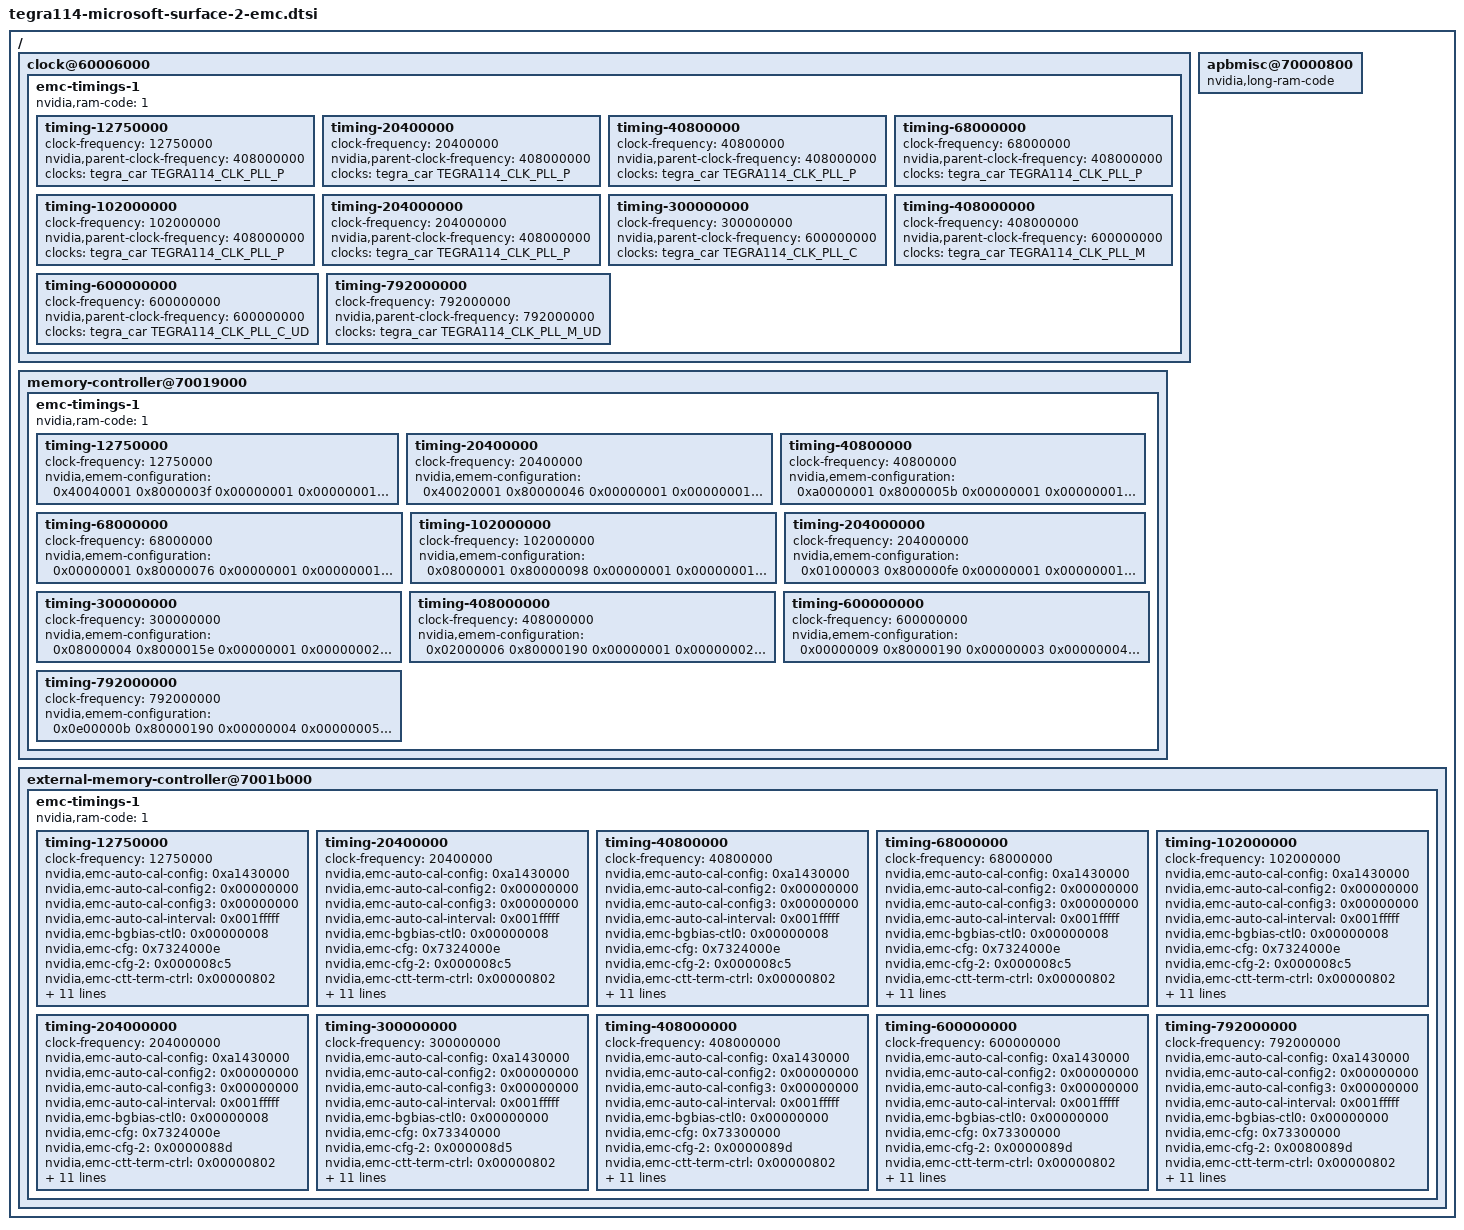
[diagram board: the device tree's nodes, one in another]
// SPDX-License-Identifier: GPL-2.0

#include <dt-bindings/clock/tegra114-car.h>

/ {
	clock@60006000 {
		emc-timings-1 {
			nvidia,ram-code = <1>;

			timing-12750000 {
				clock-frequency = <12750000>;
				nvidia,parent-clock-frequency = <408000000>;
				clocks = <&tegra_car TEGRA114_CLK_PLL_P>;
				clock-names = "emc-parent";
			};

			timing-20400000 {
				clock-frequency = <20400000>;
				nvidia,parent-clock-frequency = <408000000>;
				clocks = <&tegra_car TEGRA114_CLK_PLL_P>;
				clock-names = "emc-parent";
			};

			timing-40800000 {
				clock-frequency = <40800000>;
				nvidia,parent-clock-frequency = <408000000>;
				clocks = <&tegra_car TEGRA114_CLK_PLL_P>;
				clock-names = "emc-parent";
			};

			timing-68000000 {
				clock-frequency = <68000000>;
				nvidia,parent-clock-frequency = <408000000>;
				clocks = <&tegra_car TEGRA114_CLK_PLL_P>;
				clock-names = "emc-parent";
			};

			timing-102000000 {
				clock-frequency = <102000000>;
				nvidia,parent-clock-frequency = <408000000>;
				clocks = <&tegra_car TEGRA114_CLK_PLL_P>;
				clock-names = "emc-parent";
			};

			timing-204000000 {
				clock-frequency = <204000000>;
				nvidia,parent-clock-frequency = <408000000>;
				clocks = <&tegra_car TEGRA114_CLK_PLL_P>;
				clock-names = "emc-parent";
			};

			timing-300000000 {
				clock-frequency = <300000000>;
				nvidia,parent-clock-frequency = <600000000>;
				clocks = <&tegra_car TEGRA114_CLK_PLL_C>;
				clock-names = "emc-parent";
			};

			timing-408000000 {
				clock-frequency = <408000000>;
				nvidia,parent-clock-frequency = <600000000>;
				clocks = <&tegra_car TEGRA114_CLK_PLL_M>;
				clock-names = "emc-parent";
			};

			timing-600000000 {
				clock-frequency = <600000000>;
				nvidia,parent-clock-frequency = <600000000>;
				clocks = <&tegra_car TEGRA114_CLK_PLL_C_UD>;
				clock-names = "emc-parent";
			};

			timing-792000000 {
				clock-frequency = <792000000>;
				nvidia,parent-clock-frequency = <792000000>;
				clocks = <&tegra_car TEGRA114_CLK_PLL_M_UD>;
				clock-names = "emc-parent";
			};
		};

	};

	apbmisc@70000800 {
		nvidia,long-ram-code;
	};

	memory-controller@70019000 {
		emc-timings-1 {
			nvidia,ram-code = <1>;

			timing-12750000 {
				clock-frequency = <12750000>;

				nvidia,emem-configuration = <
			0x40040001	/* MC_EMEM_ARB_CFG */
			0x8000003f	/* MC_EMEM_ARB_OUTSTANDING_REQ */
			0x00000001	/* MC_EMEM_ARB_TIMING_RCD */
			0x00000001	/* MC_EMEM_ARB_TIMING_RP */
			0x00000002	/* MC_EMEM_ARB_TIMING_RC */
			0x00000000	/* MC_EMEM_ARB_TIMING_RAS */
			0x00000001	/* MC_EMEM_ARB_TIMING_FAW */
			0x00000001	/* MC_EMEM_ARB_TIMING_RRD */
			0x00000002	/* MC_EMEM_ARB_TIMING_RAP2PRE */
			0x00000008	/* MC_EMEM_ARB_TIMING_WAP2PRE */
			0x00000002	/* MC_EMEM_ARB_TIMING_R2R */
			0x00000001	/* MC_EMEM_ARB_TIMING_W2W */
			0x00000003	/* MC_EMEM_ARB_TIMING_R2W */
			0x00000006	/* MC_EMEM_ARB_TIMING_W2R */
			0x06030102	/* MC_EMEM_ARB_DA_TURNS */
			0x000a0402	/* MC_EMEM_ARB_DA_COVERS */
			0x77e30303	/* MC_EMEM_ARB_MISC0 */
			0x001f0000	/* MC_EMEM_ARB_RING1_THROTTLE */
				>;
			};

			timing-20400000 {
				clock-frequency = <20400000>;

				nvidia,emem-configuration = <
			0x40020001	/* MC_EMEM_ARB_CFG */
			0x80000046	/* MC_EMEM_ARB_OUTSTANDING_REQ */
			0x00000001	/* MC_EMEM_ARB_TIMING_RCD */
			0x00000001	/* MC_EMEM_ARB_TIMING_RP */
			0x00000002	/* MC_EMEM_ARB_TIMING_RC */
			0x00000000	/* MC_EMEM_ARB_TIMING_RAS */
			0x00000001	/* MC_EMEM_ARB_TIMING_FAW */
			0x00000001	/* MC_EMEM_ARB_TIMING_RRD */
			0x00000002	/* MC_EMEM_ARB_TIMING_RAP2PRE */
			0x00000008	/* MC_EMEM_ARB_TIMING_WAP2PRE */
			0x00000002	/* MC_EMEM_ARB_TIMING_R2R */
			0x00000001	/* MC_EMEM_ARB_TIMING_W2W */
			0x00000003	/* MC_EMEM_ARB_TIMING_R2W */
			0x00000006	/* MC_EMEM_ARB_TIMING_W2R */
			0x06030102	/* MC_EMEM_ARB_DA_TURNS */
			0x000a0402	/* MC_EMEM_ARB_DA_COVERS */
			0x76230303	/* MC_EMEM_ARB_MISC0 */
			0x001f0000	/* MC_EMEM_ARB_RING1_THROTTLE */
				>;
			};

			timing-40800000 {
				clock-frequency = <40800000>;

				nvidia,emem-configuration = <
			0xa0000001	/* MC_EMEM_ARB_CFG */
			0x8000005b	/* MC_EMEM_ARB_OUTSTANDING_REQ */
			0x00000001	/* MC_EMEM_ARB_TIMING_RCD */
			0x00000001	/* MC_EMEM_ARB_TIMING_RP */
			0x00000002	/* MC_EMEM_ARB_TIMING_RC */
			0x00000000	/* MC_EMEM_ARB_TIMING_RAS */
			0x00000001	/* MC_EMEM_ARB_TIMING_FAW */
			0x00000001	/* MC_EMEM_ARB_TIMING_RRD */
			0x00000002	/* MC_EMEM_ARB_TIMING_RAP2PRE */
			0x00000008	/* MC_EMEM_ARB_TIMING_WAP2PRE */
			0x00000002	/* MC_EMEM_ARB_TIMING_R2R */
			0x00000001	/* MC_EMEM_ARB_TIMING_W2W */
			0x00000003	/* MC_EMEM_ARB_TIMING_R2W */
			0x00000006	/* MC_EMEM_ARB_TIMING_W2R */
			0x06030102	/* MC_EMEM_ARB_DA_TURNS */
			0x000a0402	/* MC_EMEM_ARB_DA_COVERS */
			0x74a30303	/* MC_EMEM_ARB_MISC0 */
			0x001f0000	/* MC_EMEM_ARB_RING1_THROTTLE */
				>;
			};

			timing-68000000 {
				clock-frequency = <68000000>;

				nvidia,emem-configuration = <
			0x00000001	/* MC_EMEM_ARB_CFG */
			0x80000076	/* MC_EMEM_ARB_OUTSTANDING_REQ */
			0x00000001	/* MC_EMEM_ARB_TIMING_RCD */
			0x00000001	/* MC_EMEM_ARB_TIMING_RP */
			0x00000002	/* MC_EMEM_ARB_TIMING_RC */
			0x00000000	/* MC_EMEM_ARB_TIMING_RAS */
			0x00000001	/* MC_EMEM_ARB_TIMING_FAW */
			0x00000001	/* MC_EMEM_ARB_TIMING_RRD */
			0x00000002	/* MC_EMEM_ARB_TIMING_RAP2PRE */
			0x00000008	/* MC_EMEM_ARB_TIMING_WAP2PRE */
			0x00000002	/* MC_EMEM_ARB_TIMING_R2R */
			0x00000001	/* MC_EMEM_ARB_TIMING_W2W */
			0x00000003	/* MC_EMEM_ARB_TIMING_R2W */
			0x00000006	/* MC_EMEM_ARB_TIMING_W2R */
			0x06030102	/* MC_EMEM_ARB_DA_TURNS */
			0x000a0402	/* MC_EMEM_ARB_DA_COVERS */
			0x74230403	/* MC_EMEM_ARB_MISC0 */
			0x001f0000	/* MC_EMEM_ARB_RING1_THROTTLE */
				>;
			};

			timing-102000000 {
				clock-frequency = <102000000>;

				nvidia,emem-configuration = <
			0x08000001	/* MC_EMEM_ARB_CFG */
			0x80000098	/* MC_EMEM_ARB_OUTSTANDING_REQ */
			0x00000001	/* MC_EMEM_ARB_TIMING_RCD */
			0x00000001	/* MC_EMEM_ARB_TIMING_RP */
			0x00000003	/* MC_EMEM_ARB_TIMING_RC */
			0x00000000	/* MC_EMEM_ARB_TIMING_RAS */
			0x00000002	/* MC_EMEM_ARB_TIMING_FAW */
			0x00000001	/* MC_EMEM_ARB_TIMING_RRD */
			0x00000002	/* MC_EMEM_ARB_TIMING_RAP2PRE */
			0x00000008	/* MC_EMEM_ARB_TIMING_WAP2PRE */
			0x00000002	/* MC_EMEM_ARB_TIMING_R2R */
			0x00000001	/* MC_EMEM_ARB_TIMING_W2W */
			0x00000003	/* MC_EMEM_ARB_TIMING_R2W */
			0x00000006	/* MC_EMEM_ARB_TIMING_W2R */
			0x06030102	/* MC_EMEM_ARB_DA_TURNS */
			0x000a0403	/* MC_EMEM_ARB_DA_COVERS */
			0x73c30504	/* MC_EMEM_ARB_MISC0 */
			0x001f0000	/* MC_EMEM_ARB_RING1_THROTTLE */
				>;
			};

			timing-204000000 {
				clock-frequency = <204000000>;

				nvidia,emem-configuration = <
			0x01000003	/* MC_EMEM_ARB_CFG */
			0x800000fe	/* MC_EMEM_ARB_OUTSTANDING_REQ */
			0x00000001	/* MC_EMEM_ARB_TIMING_RCD */
			0x00000001	/* MC_EMEM_ARB_TIMING_RP */
			0x00000005	/* MC_EMEM_ARB_TIMING_RC */
			0x00000002	/* MC_EMEM_ARB_TIMING_RAS */
			0x00000004	/* MC_EMEM_ARB_TIMING_FAW */
			0x00000001	/* MC_EMEM_ARB_TIMING_RRD */
			0x00000002	/* MC_EMEM_ARB_TIMING_RAP2PRE */
			0x00000008	/* MC_EMEM_ARB_TIMING_WAP2PRE */
			0x00000002	/* MC_EMEM_ARB_TIMING_R2R */
			0x00000001	/* MC_EMEM_ARB_TIMING_W2W */
			0x00000003	/* MC_EMEM_ARB_TIMING_R2W */
			0x00000006	/* MC_EMEM_ARB_TIMING_W2R */
			0x06030102	/* MC_EMEM_ARB_DA_TURNS */
			0x000a0405	/* MC_EMEM_ARB_DA_COVERS */
			0x73840a06	/* MC_EMEM_ARB_MISC0 */
			0x001f0000	/* MC_EMEM_ARB_RING1_THROTTLE */
				>;
			};

			timing-300000000 {
				clock-frequency = <300000000>;

				nvidia,emem-configuration = <
			0x08000004	/* MC_EMEM_ARB_CFG */
			0x8000015e	/* MC_EMEM_ARB_OUTSTANDING_REQ */
			0x00000001	/* MC_EMEM_ARB_TIMING_RCD */
			0x00000002	/* MC_EMEM_ARB_TIMING_RP */
			0x00000007	/* MC_EMEM_ARB_TIMING_RC */
			0x00000004	/* MC_EMEM_ARB_TIMING_RAS */
			0x00000005	/* MC_EMEM_ARB_TIMING_FAW */
			0x00000001	/* MC_EMEM_ARB_TIMING_RRD */
			0x00000002	/* MC_EMEM_ARB_TIMING_RAP2PRE */
			0x00000007	/* MC_EMEM_ARB_TIMING_WAP2PRE */
			0x00000002	/* MC_EMEM_ARB_TIMING_R2R */
			0x00000002	/* MC_EMEM_ARB_TIMING_W2W */
			0x00000004	/* MC_EMEM_ARB_TIMING_R2W */
			0x00000006	/* MC_EMEM_ARB_TIMING_W2R */
			0x06040202	/* MC_EMEM_ARB_DA_TURNS */
			0x000b0607	/* MC_EMEM_ARB_DA_COVERS */
			0x77450e08	/* MC_EMEM_ARB_MISC0 */
			0x001f0000	/* MC_EMEM_ARB_RING1_THROTTLE */
				>;
			};


			timing-408000000 {
				clock-frequency = <408000000>;

				nvidia,emem-configuration = <
			0x02000006	/* MC_EMEM_ARB_CFG */
			0x80000190	/* MC_EMEM_ARB_OUTSTANDING_REQ */
			0x00000001	/* MC_EMEM_ARB_TIMING_RCD */
			0x00000002	/* MC_EMEM_ARB_TIMING_RP */
			0x0000000a	/* MC_EMEM_ARB_TIMING_RC */
			0x00000006	/* MC_EMEM_ARB_TIMING_RAS */
			0x00000008	/* MC_EMEM_ARB_TIMING_FAW */
			0x00000001	/* MC_EMEM_ARB_TIMING_RRD */
			0x00000002	/* MC_EMEM_ARB_TIMING_RAP2PRE */
			0x00000009	/* MC_EMEM_ARB_TIMING_WAP2PRE */
			0x00000002	/* MC_EMEM_ARB_TIMING_R2R */
			0x00000002	/* MC_EMEM_ARB_TIMING_W2W */
			0x00000004	/* MC_EMEM_ARB_TIMING_R2W */
			0x00000006	/* MC_EMEM_ARB_TIMING_W2R */
			0x06040202	/* MC_EMEM_ARB_DA_TURNS */
			0x000e070a	/* MC_EMEM_ARB_DA_COVERS */
			0x7547130b	/* MC_EMEM_ARB_MISC0 */
			0x001f0000	/* MC_EMEM_ARB_RING1_THROTTLE */
				>;
			};

			timing-600000000 {
				clock-frequency = <600000000>;

				nvidia,emem-configuration = <
			0x00000009	/* MC_EMEM_ARB_CFG */
			0x80000190	/* MC_EMEM_ARB_OUTSTANDING_REQ */
			0x00000003	/* MC_EMEM_ARB_TIMING_RCD */
			0x00000004	/* MC_EMEM_ARB_TIMING_RP */
			0x0000000e	/* MC_EMEM_ARB_TIMING_RC */
			0x00000009	/* MC_EMEM_ARB_TIMING_RAS */
			0x0000000b	/* MC_EMEM_ARB_TIMING_FAW */
			0x00000001	/* MC_EMEM_ARB_TIMING_RRD */
			0x00000003	/* MC_EMEM_ARB_TIMING_RAP2PRE */
			0x0000000b	/* MC_EMEM_ARB_TIMING_WAP2PRE */
			0x00000002	/* MC_EMEM_ARB_TIMING_R2R */
			0x00000002	/* MC_EMEM_ARB_TIMING_W2W */
			0x00000005	/* MC_EMEM_ARB_TIMING_R2W */
			0x00000007	/* MC_EMEM_ARB_TIMING_W2R */
			0x07050202	/* MC_EMEM_ARB_DA_TURNS */
			0x00130b0e	/* MC_EMEM_ARB_DA_COVERS */
			0x73a91b0f	/* MC_EMEM_ARB_MISC0 */
			0x001f0000	/* MC_EMEM_ARB_RING1_THROTTLE */
				>;
			};

			timing-792000000 {
				clock-frequency = <792000000>;

				nvidia,emem-configuration = <
			0x0e00000b	/* MC_EMEM_ARB_CFG */
			0x80000190	/* MC_EMEM_ARB_OUTSTANDING_REQ */
			0x00000004	/* MC_EMEM_ARB_TIMING_RCD */
			0x00000005	/* MC_EMEM_ARB_TIMING_RP */
			0x00000013	/* MC_EMEM_ARB_TIMING_RC */
			0x0000000c	/* MC_EMEM_ARB_TIMING_RAS */
			0x0000000f	/* MC_EMEM_ARB_TIMING_FAW */
			0x00000002	/* MC_EMEM_ARB_TIMING_RRD */
			0x00000003	/* MC_EMEM_ARB_TIMING_RAP2PRE */
			0x0000000c	/* MC_EMEM_ARB_TIMING_WAP2PRE */
			0x00000002	/* MC_EMEM_ARB_TIMING_R2R */
			0x00000002	/* MC_EMEM_ARB_TIMING_W2W */
			0x00000006	/* MC_EMEM_ARB_TIMING_R2W */
			0x00000008	/* MC_EMEM_ARB_TIMING_W2R */
			0x08060202	/* MC_EMEM_ARB_DA_TURNS */
			0x00160d13	/* MC_EMEM_ARB_DA_COVERS */
			0x734c2414	/* MC_EMEM_ARB_MISC0 */
			0x001f0000	/* MC_EMEM_ARB_RING1_THROTTLE */
				>;
			};
		};

	};

	external-memory-controller@7001b000 {
		emc-timings-1 {
			nvidia,ram-code = <1>;

			timing-12750000 {
				clock-frequency = <12750000>;

				nvidia,emc-auto-cal-config = <0xa1430000>;
				nvidia,emc-auto-cal-config2 = <0x00000000>;
				nvidia,emc-auto-cal-config3 = <0x00000000>;
				nvidia,emc-auto-cal-interval = <0x001fffff>;
				nvidia,emc-bgbias-ctl0 = <0x00000008>;
				nvidia,emc-cfg = <0x7324000e>;
				nvidia,emc-cfg-2 = <0x000008c5>;
				nvidia,emc-ctt-term-ctrl = <0x00000802>;
				nvidia,emc-mode-1 = <0x80100003>;
				nvidia,emc-mode-2 = <0x80200048>;
				nvidia,emc-mode-4 = <0x00000000>;
				nvidia,emc-mode-reset = <0x80001221>;
				nvidia,emc-mrs-wait-cnt = <0x000c000c>;
				nvidia,emc-sel-dpd-ctrl = <0x00040128>;
				nvidia,emc-xm2dqspadctrl2 = <0x0130b118>;
				nvidia,emc-zcal-cnt-long = <0x00000042>;
				nvidia,emc-zcal-interval = <0x00000000>;

				nvidia,emc-configuration = <
			0x00000000	/* EMC_RC */
			0x00000003	/* EMC_RFC */
			0x00000000	/* EMC_RFC_SLR */
			0x00000000	/* EMC_RAS */
			0x00000000	/* EMC_RP */
			0x00000004	/* EMC_R2W */
			0x0000000a	/* EMC_W2R */
			0x00000003	/* EMC_R2P */
			0x0000000b	/* EMC_W2P */
			0x00000000	/* EMC_RD_RCD */
			0x00000000	/* EMC_WR_RCD */
			0x00000003	/* EMC_RRD */
			0x00000001	/* EMC_REXT */
			0x00000000	/* EMC_WEXT */
			0x00000005	/* EMC_WDV */
			0x0000000f	/* EMC_WDV_MASK */
			0x00000006	/* EMC_IBDLY */
			0x00010000	/* EMC_PUTERM_EXTRA */
			0x00000000	/* EMC_CDB_CNTL_2 */
			0x00000004	/* EMC_QRST */
			0x0000000f	/* EMC_RDV_MASK */
			0x00000060	/* EMC_REFRESH */
			0x00000000	/* EMC_BURST_REFRESH_NUM */
			0x00000018	/* EMC_PRE_REFRESH_REQ_CNT */
			0x00000002	/* EMC_PDEX2WR */
			0x00000002	/* EMC_PDEX2RD */
			0x00000001	/* EMC_PCHG2PDEN */
			0x00000000	/* EMC_ACT2PDEN */
			0x00000007	/* EMC_AR2PDEN */
			0x0000000f	/* EMC_RW2PDEN */
			0x00000005	/* EMC_TXSR */
			0x00000005	/* EMC_TXSRDLL */
			0x00000004	/* EMC_TCKE */
			0x00000004	/* EMC_TCKESR */
			0x00000004	/* EMC_TPD */
			0x00000004	/* EMC_TFAW */
			0x00000000	/* EMC_TRPAB */
			0x00000004	/* EMC_TCLKSTABLE */
			0x00000005	/* EMC_TCLKSTOP */
			0x00000064	/* EMC_TREFBW */
			0x00000006	/* EMC_QUSE_EXTRA */
			0x00000020	/* EMC_ODT_WRITE */
			0x00000000	/* EMC_ODT_READ */
			0x0000aa88	/* EMC_FBIO_CFG5 */
			0x002c00a0	/* EMC_CFG_DIG_DLL */
			0x00008000	/* EMC_CFG_DIG_DLL_PERIOD */
			0x00078000	/* EMC_DLL_XFORM_DQS4 */
			0x00078000	/* EMC_DLL_XFORM_DQS5 */
			0x00078000	/* EMC_DLL_XFORM_DQS6 */
			0x00078000	/* EMC_DLL_XFORM_DQS7 */
			0x00000000	/* EMC_DLL_XFORM_QUSE4 */
			0x00000000	/* EMC_DLL_XFORM_QUSE5 */
			0x00000000	/* EMC_DLL_XFORM_QUSE6 */
			0x00000000	/* EMC_DLL_XFORM_QUSE7 */
			0x00000000	/* EMC_DLI_TRIM_TXDQS4 */
			0x00000000	/* EMC_DLI_TRIM_TXDQS5 */
			0x00000000	/* EMC_DLI_TRIM_TXDQS6 */
			0x00000000	/* EMC_DLI_TRIM_TXDQS7 */
			0x001112a0	/* EMC_XM2CMDPADCTRL */
			0x00000000	/* EMC_XM2CMDPADCTRL4 */
			0x0000a11c	/* EMC_XM2DQSPADCTRL2 */
			0x00000000	/* EMC_XM2DQPADCTRL2 */
			0x77ffc085	/* EMC_XM2CLKPADCTRL */
			0x81f1f108	/* EMC_XM2COMPPADCTRL */
			0x03037504	/* EMC_XM2VTTGENPADCTRL */
			0x0000003f	/* EMC_XM2VTTGENPADCTRL2 */
			0x0000003f	/* EMC_DSR_VTTGEN_DRV */
			0x00000007	/* EMC_TXDSRVTTGEN */
			0x02000000	/* EMC_FBIO_SPARE */
			0x00000802	/* EMC_CTT_TERM_CTRL */
			0x00000000	/* EMC_ZCAL_INTERVAL */
			0x00000042	/* EMC_ZCAL_WAIT_CNT */
			0x000c000c	/* EMC_MRS_WAIT_CNT */
			0x000c000c	/* EMC_MRS_WAIT_CNT2 */
			0x00000000	/* EMC_AUTO_CAL_CONFIG2 */
			0x00000000	/* EMC_AUTO_CAL_CONFIG3 */
			0x00000000	/* EMC_CTT */
			0x00000000	/* EMC_CTT_DURATION */
			0x800001c5	/* EMC_DYN_SELF_REF_CONTROL */
			0x1f7df7df	/* EMC_CA_TRAINING_TIMING_CNTL1 */
			0x0000001f	/* EMC_CA_TRAINING_TIMING_CNTL2 */
			0x00040320	/* EMC_SEL_DPD_CTRL */
			0x00000000	/* EMC_CDB_CNTL_1 */
			0x00000004	/* EMC_FBIO_CFG6 */
			0x00000007	/* EMC_QUSE */
			0x00000004	/* EMC_EINPUT */
			0x00000004	/* EMC_EINPUT_DURATION */
			0x00078000	/* EMC_DLL_XFORM_DQS0 */
			0x00000009	/* EMC_QSAFE */
			0x00000000	/* EMC_DLL_XFORM_QUSE0 */
			0x0000000d	/* EMC_RDV */
			0x00249249	/* EMC_XM2DQSPADCTRL4 */
			0x20820800	/* EMC_XM2DQSPADCTRL3 */
			0x0007c000	/* EMC_DLL_XFORM_DQ0 */
			0xa0f10f0f	/* EMC_AUTO_CAL_CONFIG */
			0x00000000	/* EMC_DLL_XFORM_ADDR0 */
			0x00000d0d	/* EMC_XM2CLKPADCTRL2 */
			0x00000000	/* EMC_DLI_TRIM_TXDQS0 */
			0x00000000	/* EMC_DLL_XFORM_ADDR1 */
			0x00000000	/* EMC_DLL_XFORM_ADDR2 */
			0x00078000	/* EMC_DLL_XFORM_DQS1 */
			0x00078000	/* EMC_DLL_XFORM_DQS2 */
			0x00078000	/* EMC_DLL_XFORM_DQS3 */
			0x0007c000	/* EMC_DLL_XFORM_DQ1 */
			0x0007c000	/* EMC_DLL_XFORM_DQ2 */
			0x0007c000	/* EMC_DLL_XFORM_DQ3 */
			0x00000000	/* EMC_DLI_TRIM_TXDQS1 */
			0x00000000	/* EMC_DLI_TRIM_TXDQS2 */
			0x00000000	/* EMC_DLI_TRIM_TXDQS3 */
			0x00000000	/* EMC_DLL_XFORM_QUSE1 */
			0x00000000	/* EMC_DLL_XFORM_QUSE2 */
			0x00000000	/* EMC_DLL_XFORM_QUSE3 */
				>;
			};

			timing-20400000 {
				clock-frequency = <20400000>;

				nvidia,emc-auto-cal-config = <0xa1430000>;
				nvidia,emc-auto-cal-config2 = <0x00000000>;
				nvidia,emc-auto-cal-config3 = <0x00000000>;
				nvidia,emc-auto-cal-interval = <0x001fffff>;
				nvidia,emc-bgbias-ctl0 = <0x00000008>;
				nvidia,emc-cfg = <0x7324000e>;
				nvidia,emc-cfg-2 = <0x000008c5>;
				nvidia,emc-ctt-term-ctrl = <0x00000802>;
				nvidia,emc-mode-1 = <0x80100003>;
				nvidia,emc-mode-2 = <0x80200048>;
				nvidia,emc-mode-4 = <0x00000000>;
				nvidia,emc-mode-reset = <0x80001221>;
				nvidia,emc-mrs-wait-cnt = <0x000c000c>;
				nvidia,emc-sel-dpd-ctrl = <0x00040128>;
				nvidia,emc-xm2dqspadctrl2 = <0x0130b118>;
				nvidia,emc-zcal-cnt-long = <0x00000042>;
				nvidia,emc-zcal-interval = <0x00000000>;

				nvidia,emc-configuration = <
							0x00000000	/* EMC_RC */
			0x00000005	/* EMC_RFC */
			0x00000000	/* EMC_RFC_SLR */
			0x00000000	/* EMC_RAS */
			0x00000000	/* EMC_RP */
			0x00000004	/* EMC_R2W */
			0x0000000a	/* EMC_W2R */
			0x00000003	/* EMC_R2P */
			0x0000000b	/* EMC_W2P */
			0x00000000	/* EMC_RD_RCD */
			0x00000000	/* EMC_WR_RCD */
			0x00000003	/* EMC_RRD */
			0x00000001	/* EMC_REXT */
			0x00000000	/* EMC_WEXT */
			0x00000005	/* EMC_WDV */
			0x0000000f	/* EMC_WDV_MASK */
			0x00000006	/* EMC_IBDLY */
			0x00010000	/* EMC_PUTERM_EXTRA */
			0x00000000	/* EMC_CDB_CNTL_2 */
			0x00000004	/* EMC_QRST */
			0x0000000f	/* EMC_RDV_MASK */
			0x0000009a	/* EMC_REFRESH */
			0x00000000	/* EMC_BURST_REFRESH_NUM */
			0x00000026	/* EMC_PRE_REFRESH_REQ_CNT */
			0x00000002	/* EMC_PDEX2WR */
			0x00000002	/* EMC_PDEX2RD */
			0x00000001	/* EMC_PCHG2PDEN */
			0x00000000	/* EMC_ACT2PDEN */
			0x00000007	/* EMC_AR2PDEN */
			0x0000000f	/* EMC_RW2PDEN */
			0x00000006	/* EMC_TXSR */
			0x00000006	/* EMC_TXSRDLL */
			0x00000004	/* EMC_TCKE */
			0x00000004	/* EMC_TCKESR */
			0x00000004	/* EMC_TPD */
			0x00000004	/* EMC_TFAW */
			0x00000000	/* EMC_TRPAB */
			0x00000004	/* EMC_TCLKSTABLE */
			0x00000005	/* EMC_TCLKSTOP */
			0x000000a0	/* EMC_TREFBW */
			0x00000006	/* EMC_QUSE_EXTRA */
			0x00000020	/* EMC_ODT_WRITE */
			0x00000000	/* EMC_ODT_READ */
			0x0000aa88	/* EMC_FBIO_CFG5 */
			0x002c00a0	/* EMC_CFG_DIG_DLL */
			0x00008000	/* EMC_CFG_DIG_DLL_PERIOD */
			0x00078000	/* EMC_DLL_XFORM_DQS4 */
			0x00078000	/* EMC_DLL_XFORM_DQS5 */
			0x00078000	/* EMC_DLL_XFORM_DQS6 */
			0x00078000	/* EMC_DLL_XFORM_DQS7 */
			0x00000000	/* EMC_DLL_XFORM_QUSE4 */
			0x00000000	/* EMC_DLL_XFORM_QUSE5 */
			0x00000000	/* EMC_DLL_XFORM_QUSE6 */
			0x00000000	/* EMC_DLL_XFORM_QUSE7 */
			0x00000000	/* EMC_DLI_TRIM_TXDQS4 */
			0x00000000	/* EMC_DLI_TRIM_TXDQS5 */
			0x00000000	/* EMC_DLI_TRIM_TXDQS6 */
			0x00000000	/* EMC_DLI_TRIM_TXDQS7 */
			0x001112a0	/* EMC_XM2CMDPADCTRL */
			0x00000000	/* EMC_XM2CMDPADCTRL4 */
			0x0000a11c	/* EMC_XM2DQSPADCTRL2 */
			0x00000000	/* EMC_XM2DQPADCTRL2 */
			0x77ffc085	/* EMC_XM2CLKPADCTRL */
			0x81f1f108	/* EMC_XM2COMPPADCTRL */
			0x03037504	/* EMC_XM2VTTGENPADCTRL */
			0x0000003f	/* EMC_XM2VTTGENPADCTRL2 */
			0x0000003f	/* EMC_DSR_VTTGEN_DRV */
			0x0000000b	/* EMC_TXDSRVTTGEN */
			0x02000000	/* EMC_FBIO_SPARE */
			0x00000802	/* EMC_CTT_TERM_CTRL */
			0x00000000	/* EMC_ZCAL_INTERVAL */
			0x00000042	/* EMC_ZCAL_WAIT_CNT */
			0x000c000c	/* EMC_MRS_WAIT_CNT */
			0x000c000c	/* EMC_MRS_WAIT_CNT2 */
			0x00000000	/* EMC_AUTO_CAL_CONFIG2 */
			0x00000000	/* EMC_AUTO_CAL_CONFIG3 */
			0x00000000	/* EMC_CTT */
			0x00000000	/* EMC_CTT_DURATION */
			0x8000023a	/* EMC_DYN_SELF_REF_CONTROL */
			0x1f7df7df	/* EMC_CA_TRAINING_TIMING_CNTL1 */
			0x0000001f	/* EMC_CA_TRAINING_TIMING_CNTL2 */
			0x00040320	/* EMC_SEL_DPD_CTRL */
			0x00000000	/* EMC_CDB_CNTL_1 */
			0x00000004	/* EMC_FBIO_CFG6 */
			0x00000007	/* EMC_QUSE */
			0x00000004	/* EMC_EINPUT */
			0x00000004	/* EMC_EINPUT_DURATION */
			0x00078000	/* EMC_DLL_XFORM_DQS0 */
			0x00000009	/* EMC_QSAFE */
			0x00000000	/* EMC_DLL_XFORM_QUSE0 */
			0x0000000d	/* EMC_RDV */
			0x00249249	/* EMC_XM2DQSPADCTRL4 */
			0x20820800	/* EMC_XM2DQSPADCTRL3 */
			0x0007c000	/* EMC_DLL_XFORM_DQ0 */
			0xa0f10f0f	/* EMC_AUTO_CAL_CONFIG */
			0x00000000	/* EMC_DLL_XFORM_ADDR0 */
			0x00000d0d	/* EMC_XM2CLKPADCTRL2 */
			0x00000000	/* EMC_DLI_TRIM_TXDQS0 */
			0x00000000	/* EMC_DLL_XFORM_ADDR1 */
			0x00000000	/* EMC_DLL_XFORM_ADDR2 */
			0x00078000	/* EMC_DLL_XFORM_DQS1 */
			0x00078000	/* EMC_DLL_XFORM_DQS2 */
			0x00078000	/* EMC_DLL_XFORM_DQS3 */
			0x0007c000	/* EMC_DLL_XFORM_DQ1 */
			0x0007c000	/* EMC_DLL_XFORM_DQ2 */
			0x0007c000	/* EMC_DLL_XFORM_DQ3 */
			0x00000000	/* EMC_DLI_TRIM_TXDQS1 */
			0x00000000	/* EMC_DLI_TRIM_TXDQS2 */
			0x00000000	/* EMC_DLI_TRIM_TXDQS3 */
			0x00000000	/* EMC_DLL_XFORM_QUSE1 */
			0x00000000	/* EMC_DLL_XFORM_QUSE2 */
			0x00000000	/* EMC_DLL_XFORM_QUSE3 */
				>;
			};

			timing-40800000 {
				clock-frequency = <40800000>;

				nvidia,emc-auto-cal-config = <0xa1430000>;
				nvidia,emc-auto-cal-config2 = <0x00000000>;
				nvidia,emc-auto-cal-config3 = <0x00000000>;
				nvidia,emc-auto-cal-interval = <0x001fffff>;
				nvidia,emc-bgbias-ctl0 = <0x00000008>;
				nvidia,emc-cfg = <0x7324000e>;
				nvidia,emc-cfg-2 = <0x000008c5>;
				nvidia,emc-ctt-term-ctrl = <0x00000802>;
				nvidia,emc-mode-1 = <0x80100003>;
				nvidia,emc-mode-2 = <0x80200048>;
				nvidia,emc-mode-4 = <0x00000000>;
				nvidia,emc-mode-reset = <0x80001221>;
				nvidia,emc-mrs-wait-cnt = <0x000c000c>;
				nvidia,emc-sel-dpd-ctrl = <0x00040128>;
				nvidia,emc-xm2dqspadctrl2 = <0x0130b118>;
				nvidia,emc-zcal-cnt-long = <0x00000042>;
				nvidia,emc-zcal-interval = <0x00000000>;

				nvidia,emc-configuration = <
			0x00000001	/* EMC_RC */
			0x0000000a	/* EMC_RFC */
			0x00000000	/* EMC_RFC_SLR */
			0x00000001	/* EMC_RAS */
			0x00000000	/* EMC_RP */
			0x00000004	/* EMC_R2W */
			0x0000000a	/* EMC_W2R */
			0x00000003	/* EMC_R2P */
			0x0000000b	/* EMC_W2P */
			0x00000000	/* EMC_RD_RCD */
			0x00000000	/* EMC_WR_RCD */
			0x00000003	/* EMC_RRD */
			0x00000001	/* EMC_REXT */
			0x00000000	/* EMC_WEXT */
			0x00000005	/* EMC_WDV */
			0x0000000f	/* EMC_WDV_MASK */
			0x00000006	/* EMC_IBDLY */
			0x00010000	/* EMC_PUTERM_EXTRA */
			0x00000000	/* EMC_CDB_CNTL_2 */
			0x00000004	/* EMC_QRST */
			0x0000000f	/* EMC_RDV_MASK */
			0x00000134	/* EMC_REFRESH */
			0x00000000	/* EMC_BURST_REFRESH_NUM */
			0x0000004d	/* EMC_PRE_REFRESH_REQ_CNT */
			0x00000002	/* EMC_PDEX2WR */
			0x00000002	/* EMC_PDEX2RD */
			0x00000001	/* EMC_PCHG2PDEN */
			0x00000000	/* EMC_ACT2PDEN */
			0x00000008	/* EMC_AR2PDEN */
			0x0000000f	/* EMC_RW2PDEN */
			0x0000000c	/* EMC_TXSR */
			0x0000000c	/* EMC_TXSRDLL */
			0x00000004	/* EMC_TCKE */
			0x00000004	/* EMC_TCKESR */
			0x00000004	/* EMC_TPD */
			0x00000004	/* EMC_TFAW */
			0x00000000	/* EMC_TRPAB */
			0x00000004	/* EMC_TCLKSTABLE */
			0x00000005	/* EMC_TCLKSTOP */
			0x0000013f	/* EMC_TREFBW */
			0x00000006	/* EMC_QUSE_EXTRA */
			0x00000020	/* EMC_ODT_WRITE */
			0x00000000	/* EMC_ODT_READ */
			0x0000aa88	/* EMC_FBIO_CFG5 */
			0x002c00a0	/* EMC_CFG_DIG_DLL */
			0x00008000	/* EMC_CFG_DIG_DLL_PERIOD */
			0x00078000	/* EMC_DLL_XFORM_DQS4 */
			0x00078000	/* EMC_DLL_XFORM_DQS5 */
			0x00078000	/* EMC_DLL_XFORM_DQS6 */
			0x00078000	/* EMC_DLL_XFORM_DQS7 */
			0x00000000	/* EMC_DLL_XFORM_QUSE4 */
			0x00000000	/* EMC_DLL_XFORM_QUSE5 */
			0x00000000	/* EMC_DLL_XFORM_QUSE6 */
			0x00000000	/* EMC_DLL_XFORM_QUSE7 */
			0x00000000	/* EMC_DLI_TRIM_TXDQS4 */
			0x00000000	/* EMC_DLI_TRIM_TXDQS5 */
			0x00000000	/* EMC_DLI_TRIM_TXDQS6 */
			0x00000000	/* EMC_DLI_TRIM_TXDQS7 */
			0x001112a0	/* EMC_XM2CMDPADCTRL */
			0x00000000	/* EMC_XM2CMDPADCTRL4 */
			0x0000a11c	/* EMC_XM2DQSPADCTRL2 */
			0x00000000	/* EMC_XM2DQPADCTRL2 */
			0x77ffc085	/* EMC_XM2CLKPADCTRL */
			0x81f1f108	/* EMC_XM2COMPPADCTRL */
			0x03037504	/* EMC_XM2VTTGENPADCTRL */
			0x0000003f	/* EMC_XM2VTTGENPADCTRL2 */
			0x0000003f	/* EMC_DSR_VTTGEN_DRV */
			0x00000015	/* EMC_TXDSRVTTGEN */
			0x02000000	/* EMC_FBIO_SPARE */
			0x00000802	/* EMC_CTT_TERM_CTRL */
			0x00000000	/* EMC_ZCAL_INTERVAL */
			0x00000042	/* EMC_ZCAL_WAIT_CNT */
			0x000c000c	/* EMC_MRS_WAIT_CNT */
			0x000c000c	/* EMC_MRS_WAIT_CNT2 */
			0x00000000	/* EMC_AUTO_CAL_CONFIG2 */
			0x00000000	/* EMC_AUTO_CAL_CONFIG3 */
			0x00000000	/* EMC_CTT */
			0x00000000	/* EMC_CTT_DURATION */
			0x80000370	/* EMC_DYN_SELF_REF_CONTROL */
			0x1f7df7df	/* EMC_CA_TRAINING_TIMING_CNTL1 */
			0x0000001f	/* EMC_CA_TRAINING_TIMING_CNTL2 */
			0x00040320	/* EMC_SEL_DPD_CTRL */
			0x00000000	/* EMC_CDB_CNTL_1 */
			0x00000004	/* EMC_FBIO_CFG6 */
			0x00000007	/* EMC_QUSE */
			0x00000004	/* EMC_EINPUT */
			0x00000004	/* EMC_EINPUT_DURATION */
			0x00078000	/* EMC_DLL_XFORM_DQS0 */
			0x00000009	/* EMC_QSAFE */
			0x00000000	/* EMC_DLL_XFORM_QUSE0 */
			0x0000000d	/* EMC_RDV */
			0x00249249	/* EMC_XM2DQSPADCTRL4 */
			0x20820800	/* EMC_XM2DQSPADCTRL3 */
			0x0007c000	/* EMC_DLL_XFORM_DQ0 */
			0xa0f10f0f	/* EMC_AUTO_CAL_CONFIG */
			0x00000000	/* EMC_DLL_XFORM_ADDR0 */
			0x00000d0d	/* EMC_XM2CLKPADCTRL2 */
			0x00000000	/* EMC_DLI_TRIM_TXDQS0 */
			0x00000000	/* EMC_DLL_XFORM_ADDR1 */
			0x00000000	/* EMC_DLL_XFORM_ADDR2 */
			0x00078000	/* EMC_DLL_XFORM_DQS1 */
			0x00078000	/* EMC_DLL_XFORM_DQS2 */
			0x00078000	/* EMC_DLL_XFORM_DQS3 */
			0x0007c000	/* EMC_DLL_XFORM_DQ1 */
			0x0007c000	/* EMC_DLL_XFORM_DQ2 */
			0x0007c000	/* EMC_DLL_XFORM_DQ3 */
			0x00000000	/* EMC_DLI_TRIM_TXDQS1 */
			0x00000000	/* EMC_DLI_TRIM_TXDQS2 */
			0x00000000	/* EMC_DLI_TRIM_TXDQS3 */
			0x00000000	/* EMC_DLL_XFORM_QUSE1 */
			0x00000000	/* EMC_DLL_XFORM_QUSE2 */
			0x00000000	/* EMC_DLL_XFORM_QUSE3 */				>;
			};

			timing-68000000 {
				clock-frequency = <68000000>;

				nvidia,emc-auto-cal-config = <0xa1430000>;
				nvidia,emc-auto-cal-config2 = <0x00000000>;
				nvidia,emc-auto-cal-config3 = <0x00000000>;
				nvidia,emc-auto-cal-interval = <0x001fffff>;
				nvidia,emc-bgbias-ctl0 = <0x00000008>;
				nvidia,emc-cfg = <0x7324000e>;
				nvidia,emc-cfg-2 = <0x000008c5>;
				nvidia,emc-ctt-term-ctrl = <0x00000802>;
				nvidia,emc-mode-1 = <0x80100003>;
				nvidia,emc-mode-2 = <0x80200048>;
				nvidia,emc-mode-4 = <0x00000000>;
				nvidia,emc-mode-reset = <0x80001221>;
				nvidia,emc-mrs-wait-cnt = <0x000c000c>;
				nvidia,emc-sel-dpd-ctrl = <0x00040128>;
				nvidia,emc-xm2dqspadctrl2 = <0x0130b118>;
				nvidia,emc-zcal-cnt-long = <0x00000042>;
				nvidia,emc-zcal-interval = <0x00000000>;

				nvidia,emc-configuration = <
			0x00000003	/* EMC_RC */
			0x00000011	/* EMC_RFC */
			0x00000000	/* EMC_RFC_SLR */
			0x00000002	/* EMC_RAS */
			0x00000000	/* EMC_RP */
			0x00000004	/* EMC_R2W */
			0x0000000a	/* EMC_W2R */
			0x00000003	/* EMC_R2P */
			0x0000000b	/* EMC_W2P */
			0x00000000	/* EMC_RD_RCD */
			0x00000000	/* EMC_WR_RCD */
			0x00000003	/* EMC_RRD */
			0x00000001	/* EMC_REXT */
			0x00000000	/* EMC_WEXT */
			0x00000005	/* EMC_WDV */
			0x0000000f	/* EMC_WDV_MASK */
			0x00000006	/* EMC_IBDLY */
			0x00010000	/* EMC_PUTERM_EXTRA */
			0x00000000	/* EMC_CDB_CNTL_2 */
			0x00000004	/* EMC_QRST */
			0x0000000f	/* EMC_RDV_MASK */
			0x00000202	/* EMC_REFRESH */
			0x00000000	/* EMC_BURST_REFRESH_NUM */
			0x00000080	/* EMC_PRE_REFRESH_REQ_CNT */
			0x00000002	/* EMC_PDEX2WR */
			0x00000002	/* EMC_PDEX2RD */
			0x00000001	/* EMC_PCHG2PDEN */
			0x00000000	/* EMC_ACT2PDEN */
			0x0000000f	/* EMC_AR2PDEN */
			0x0000000f	/* EMC_RW2PDEN */
			0x00000013	/* EMC_TXSR */
			0x00000013	/* EMC_TXSRDLL */
			0x00000004	/* EMC_TCKE */
			0x00000004	/* EMC_TCKESR */
			0x00000004	/* EMC_TPD */
			0x00000004	/* EMC_TFAW */
			0x00000000	/* EMC_TRPAB */
			0x00000004	/* EMC_TCLKSTABLE */
			0x00000005	/* EMC_TCLKSTOP */
			0x00000213	/* EMC_TREFBW */
			0x00000006	/* EMC_QUSE_EXTRA */
			0x00000020	/* EMC_ODT_WRITE */
			0x00000000	/* EMC_ODT_READ */
			0x0000aa88	/* EMC_FBIO_CFG5 */
			0x002c00a0	/* EMC_CFG_DIG_DLL */
			0x00008000	/* EMC_CFG_DIG_DLL_PERIOD */
			0x00078000	/* EMC_DLL_XFORM_DQS4 */
			0x00078000	/* EMC_DLL_XFORM_DQS5 */
			0x00078000	/* EMC_DLL_XFORM_DQS6 */
			0x00078000	/* EMC_DLL_XFORM_DQS7 */
			0x00000000	/* EMC_DLL_XFORM_QUSE4 */
			0x00000000	/* EMC_DLL_XFORM_QUSE5 */
			0x00000000	/* EMC_DLL_XFORM_QUSE6 */
			0x00000000	/* EMC_DLL_XFORM_QUSE7 */
			0x00000000	/* EMC_DLI_TRIM_TXDQS4 */
			0x00000000	/* EMC_DLI_TRIM_TXDQS5 */
			0x00000000	/* EMC_DLI_TRIM_TXDQS6 */
			0x00000000	/* EMC_DLI_TRIM_TXDQS7 */
			0x001112a0	/* EMC_XM2CMDPADCTRL */
			0x00000000	/* EMC_XM2CMDPADCTRL4 */
			0x0000a11c	/* EMC_XM2DQSPADCTRL2 */
			0x00000000	/* EMC_XM2DQPADCTRL2 */
			0x77ffc085	/* EMC_XM2CLKPADCTRL */
			0x81f1f108	/* EMC_XM2COMPPADCTRL */
			0x03037504	/* EMC_XM2VTTGENPADCTRL */
			0x0000003f	/* EMC_XM2VTTGENPADCTRL2 */
			0x0000003f	/* EMC_DSR_VTTGEN_DRV */
			0x00000022	/* EMC_TXDSRVTTGEN */
			0x02000000	/* EMC_FBIO_SPARE */
			0x00000802	/* EMC_CTT_TERM_CTRL */
			0x00000000	/* EMC_ZCAL_INTERVAL */
			0x00000042	/* EMC_ZCAL_WAIT_CNT */
			0x000c000c	/* EMC_MRS_WAIT_CNT */
			0x000c000c	/* EMC_MRS_WAIT_CNT2 */
			0x00000000	/* EMC_AUTO_CAL_CONFIG2 */
			0x00000000	/* EMC_AUTO_CAL_CONFIG3 */
			0x00000000	/* EMC_CTT */
			0x00000000	/* EMC_CTT_DURATION */
			0x8000050e	/* EMC_DYN_SELF_REF_CONTROL */
			0x1f7df7df	/* EMC_CA_TRAINING_TIMING_CNTL1 */
			0x0000001f	/* EMC_CA_TRAINING_TIMING_CNTL2 */
			0x00040320	/* EMC_SEL_DPD_CTRL */
			0x00000000	/* EMC_CDB_CNTL_1 */
			0x00000004	/* EMC_FBIO_CFG6 */
			0x00000007	/* EMC_QUSE */
			0x00000004	/* EMC_EINPUT */
			0x00000004	/* EMC_EINPUT_DURATION */
			0x00078000	/* EMC_DLL_XFORM_DQS0 */
			0x00000009	/* EMC_QSAFE */
			0x00000000	/* EMC_DLL_XFORM_QUSE0 */
			0x0000000d	/* EMC_RDV */
			0x00249249	/* EMC_XM2DQSPADCTRL4 */
			0x20820800	/* EMC_XM2DQSPADCTRL3 */
			0x0007c000	/* EMC_DLL_XFORM_DQ0 */
			0xa0f10f0f	/* EMC_AUTO_CAL_CONFIG */
			0x00000000	/* EMC_DLL_XFORM_ADDR0 */
			0x00000d0d	/* EMC_XM2CLKPADCTRL2 */
			0x00000000	/* EMC_DLI_TRIM_TXDQS0 */
			0x00000000	/* EMC_DLL_XFORM_ADDR1 */
			0x00000000	/* EMC_DLL_XFORM_ADDR2 */
			0x00078000	/* EMC_DLL_XFORM_DQS1 */
			0x00078000	/* EMC_DLL_XFORM_DQS2 */
			0x00078000	/* EMC_DLL_XFORM_DQS3 */
			0x0007c000	/* EMC_DLL_XFORM_DQ1 */
			0x0007c000	/* EMC_DLL_XFORM_DQ2 */
			0x0007c000	/* EMC_DLL_XFORM_DQ3 */
			0x00000000	/* EMC_DLI_TRIM_TXDQS1 */
			0x00000000	/* EMC_DLI_TRIM_TXDQS2 */
			0x00000000	/* EMC_DLI_TRIM_TXDQS3 */
			0x00000000	/* EMC_DLL_XFORM_QUSE1 */
			0x00000000	/* EMC_DLL_XFORM_QUSE2 */
			0x00000000	/* EMC_DLL_XFORM_QUSE3 */
				>;
			};

			timing-102000000 {
				clock-frequency = <102000000>;

				nvidia,emc-auto-cal-config = <0xa1430000>;
				nvidia,emc-auto-cal-config2 = <0x00000000>;
				nvidia,emc-auto-cal-config3 = <0x00000000>;
				nvidia,emc-auto-cal-interval = <0x001fffff>;
				nvidia,emc-bgbias-ctl0 = <0x00000008>;
				nvidia,emc-cfg = <0x7324000e>;
				nvidia,emc-cfg-2 = <0x000008c5>;
				nvidia,emc-ctt-term-ctrl = <0x00000802>;
				nvidia,emc-mode-1 = <0x80100003>;
				nvidia,emc-mode-2 = <0x80200048>;
				nvidia,emc-mode-4 = <0x00000000>;
				nvidia,emc-mode-reset = <0x80001221>;
				nvidia,emc-mrs-wait-cnt = <0x000c000c>;
				nvidia,emc-sel-dpd-ctrl = <0x00040128>;
				nvidia,emc-xm2dqspadctrl2 = <0x0130b118>;
				nvidia,emc-zcal-cnt-long = <0x00000042>;
				nvidia,emc-zcal-interval = <0x00000000>;

				nvidia,emc-configuration = <
			0x00000004	/* EMC_RC */
			0x0000001a	/* EMC_RFC */
			0x00000000	/* EMC_RFC_SLR */
			0x00000003	/* EMC_RAS */
			0x00000001	/* EMC_RP */
			0x00000004	/* EMC_R2W */
			0x0000000a	/* EMC_W2R */
			0x00000003	/* EMC_R2P */
			0x0000000b	/* EMC_W2P */
			0x00000001	/* EMC_RD_RCD */
			0x00000001	/* EMC_WR_RCD */
			0x00000003	/* EMC_RRD */
			0x00000001	/* EMC_REXT */
			0x00000000	/* EMC_WEXT */
			0x00000005	/* EMC_WDV */
			0x0000000f	/* EMC_WDV_MASK */
			0x00000006	/* EMC_IBDLY */
			0x00010000	/* EMC_PUTERM_EXTRA */
			0x00000000	/* EMC_CDB_CNTL_2 */
			0x00000004	/* EMC_QRST */
			0x0000000f	/* EMC_RDV_MASK */
			0x00000303	/* EMC_REFRESH */
			0x00000000	/* EMC_BURST_REFRESH_NUM */
			0x000000c0	/* EMC_PRE_REFRESH_REQ_CNT */
			0x00000002	/* EMC_PDEX2WR */
			0x00000002	/* EMC_PDEX2RD */
			0x00000001	/* EMC_PCHG2PDEN */
			0x00000000	/* EMC_ACT2PDEN */
			0x00000018	/* EMC_AR2PDEN */
			0x0000000f	/* EMC_RW2PDEN */
			0x0000001c	/* EMC_TXSR */
			0x0000001c	/* EMC_TXSRDLL */
			0x00000004	/* EMC_TCKE */
			0x00000004	/* EMC_TCKESR */
			0x00000004	/* EMC_TPD */
			0x00000005	/* EMC_TFAW */
			0x00000000	/* EMC_TRPAB */
			0x00000004	/* EMC_TCLKSTABLE */
			0x00000005	/* EMC_TCLKSTOP */
			0x0000031c	/* EMC_TREFBW */
			0x00000006	/* EMC_QUSE_EXTRA */
			0x00000020	/* EMC_ODT_WRITE */
			0x00000000	/* EMC_ODT_READ */
			0x0000aa88	/* EMC_FBIO_CFG5 */
			0x002c00a0	/* EMC_CFG_DIG_DLL */
			0x00008000	/* EMC_CFG_DIG_DLL_PERIOD */
			0x00078000	/* EMC_DLL_XFORM_DQS4 */
			0x00078000	/* EMC_DLL_XFORM_DQS5 */
			0x00078000	/* EMC_DLL_XFORM_DQS6 */
			0x00078000	/* EMC_DLL_XFORM_DQS7 */
			0x00000000	/* EMC_DLL_XFORM_QUSE4 */
			0x00000000	/* EMC_DLL_XFORM_QUSE5 */
			0x00000000	/* EMC_DLL_XFORM_QUSE6 */
			0x00000000	/* EMC_DLL_XFORM_QUSE7 */
			0x00000000	/* EMC_DLI_TRIM_TXDQS4 */
			0x00000000	/* EMC_DLI_TRIM_TXDQS5 */
			0x00000000	/* EMC_DLI_TRIM_TXDQS6 */
			0x00000000	/* EMC_DLI_TRIM_TXDQS7 */
			0x001112a0	/* EMC_XM2CMDPADCTRL */
			0x00000000	/* EMC_XM2CMDPADCTRL4 */
			0x0000a11c	/* EMC_XM2DQSPADCTRL2 */
			0x00000000	/* EMC_XM2DQPADCTRL2 */
			0x77ffc085	/* EMC_XM2CLKPADCTRL */
			0x81f1f108	/* EMC_XM2COMPPADCTRL */
			0x03037504	/* EMC_XM2VTTGENPADCTRL */
			0x0000003f	/* EMC_XM2VTTGENPADCTRL2 */
			0x0000003f	/* EMC_DSR_VTTGEN_DRV */
			0x00000033	/* EMC_TXDSRVTTGEN */
			0x02000000	/* EMC_FBIO_SPARE */
			0x00000802	/* EMC_CTT_TERM_CTRL */
			0x00000000	/* EMC_ZCAL_INTERVAL */
			0x00000042	/* EMC_ZCAL_WAIT_CNT */
			0x000c000c	/* EMC_MRS_WAIT_CNT */
			0x000c000c	/* EMC_MRS_WAIT_CNT2 */
			0x00000000	/* EMC_AUTO_CAL_CONFIG2 */
			0x00000000	/* EMC_AUTO_CAL_CONFIG3 */
			0x00000000	/* EMC_CTT */
			0x00000000	/* EMC_CTT_DURATION */
			0x80000713	/* EMC_DYN_SELF_REF_CONTROL */
			0x1f7df7df	/* EMC_CA_TRAINING_TIMING_CNTL1 */
			0x0000001f	/* EMC_CA_TRAINING_TIMING_CNTL2 */
			0x00040320	/* EMC_SEL_DPD_CTRL */
			0x00000000	/* EMC_CDB_CNTL_1 */
			0x00000004	/* EMC_FBIO_CFG6 */
			0x00000007	/* EMC_QUSE */
			0x00000004	/* EMC_EINPUT */
			0x00000004	/* EMC_EINPUT_DURATION */
			0x00078000	/* EMC_DLL_XFORM_DQS0 */
			0x00000009	/* EMC_QSAFE */
			0x00000000	/* EMC_DLL_XFORM_QUSE0 */
			0x0000000d	/* EMC_RDV */
			0x00249249	/* EMC_XM2DQSPADCTRL4 */
			0x20820800	/* EMC_XM2DQSPADCTRL3 */
			0x0007c000	/* EMC_DLL_XFORM_DQ0 */
			0xa0f10f0f	/* EMC_AUTO_CAL_CONFIG */
			0x00000000	/* EMC_DLL_XFORM_ADDR0 */
			0x00000d0d	/* EMC_XM2CLKPADCTRL2 */
			0x00000000	/* EMC_DLI_TRIM_TXDQS0 */
			0x00000000	/* EMC_DLL_XFORM_ADDR1 */
			0x00000000	/* EMC_DLL_XFORM_ADDR2 */
			0x00078000	/* EMC_DLL_XFORM_DQS1 */
			0x00078000	/* EMC_DLL_XFORM_DQS2 */
			0x00078000	/* EMC_DLL_XFORM_DQS3 */
			0x0007c000	/* EMC_DLL_XFORM_DQ1 */
			0x0007c000	/* EMC_DLL_XFORM_DQ2 */
			0x0007c000	/* EMC_DLL_XFORM_DQ3 */
			0x00000000	/* EMC_DLI_TRIM_TXDQS1 */
			0x00000000	/* EMC_DLI_TRIM_TXDQS2 */
			0x00000000	/* EMC_DLI_TRIM_TXDQS3 */
			0x00000000	/* EMC_DLL_XFORM_QUSE1 */
			0x00000000	/* EMC_DLL_XFORM_QUSE2 */
			0x00000000	/* EMC_DLL_XFORM_QUSE3 */
				>;
			};

			timing-204000000 {
				clock-frequency = <204000000>;

				nvidia,emc-auto-cal-config = <0xa1430000>;
				nvidia,emc-auto-cal-config2 = <0x00000000>;
				nvidia,emc-auto-cal-config3 = <0x00000000>;
				nvidia,emc-auto-cal-interval = <0x001fffff>;
				nvidia,emc-bgbias-ctl0 = <0x00000008>;
				nvidia,emc-cfg = <0x7324000e>;
				nvidia,emc-cfg-2 = <0x0000088d>;
				nvidia,emc-ctt-term-ctrl = <0x00000802>;
				nvidia,emc-mode-1 = <0x80100003>;
				nvidia,emc-mode-2 = <0x80200048>;
				nvidia,emc-mode-4 = <0x00000000>;
				nvidia,emc-mode-reset = <0x80001221>;
				nvidia,emc-mrs-wait-cnt = <0x000c000c>;
				nvidia,emc-sel-dpd-ctrl = <0x00040008>;
				nvidia,emc-xm2dqspadctrl2 = <0x0130b118>;
				nvidia,emc-zcal-cnt-long = <0x00000042>;
				nvidia,emc-zcal-interval = <0x00020000>;

				nvidia,emc-configuration = <
			0x00000009	/* EMC_RC */
			0x00000035	/* EMC_RFC */
			0x00000000	/* EMC_RFC_SLR */
			0x00000007	/* EMC_RAS */
			0x00000002	/* EMC_RP */
			0x00000004	/* EMC_R2W */
			0x0000000a	/* EMC_W2R */
			0x00000003	/* EMC_R2P */
			0x0000000b	/* EMC_W2P */
			0x00000002	/* EMC_RD_RCD */
			0x00000002	/* EMC_WR_RCD */
			0x00000003	/* EMC_RRD */
			0x00000001	/* EMC_REXT */
			0x00000000	/* EMC_WEXT */
			0x00000005	/* EMC_WDV */
			0x0000000f	/* EMC_WDV_MASK */
			0x00000006	/* EMC_IBDLY */
			0x00010000	/* EMC_PUTERM_EXTRA */
			0x00000000	/* EMC_CDB_CNTL_2 */
			0x00000004	/* EMC_QRST */
			0x0000000f	/* EMC_RDV_MASK */
			0x00000607	/* EMC_REFRESH */
			0x00000000	/* EMC_BURST_REFRESH_NUM */
			0x00000181	/* EMC_PRE_REFRESH_REQ_CNT */
			0x00000002	/* EMC_PDEX2WR */
			0x00000002	/* EMC_PDEX2RD */
			0x00000001	/* EMC_PCHG2PDEN */
			0x00000000	/* EMC_ACT2PDEN */
			0x00000032	/* EMC_AR2PDEN */
			0x0000000f	/* EMC_RW2PDEN */
			0x00000038	/* EMC_TXSR */
			0x00000038	/* EMC_TXSRDLL */
			0x00000004	/* EMC_TCKE */
			0x00000004	/* EMC_TCKESR */
			0x00000004	/* EMC_TPD */
			0x00000009	/* EMC_TFAW */
			0x00000000	/* EMC_TRPAB */
			0x00000004	/* EMC_TCLKSTABLE */
			0x00000005	/* EMC_TCLKSTOP */
			0x00000638	/* EMC_TREFBW */
			0x00000006	/* EMC_QUSE_EXTRA */
			0x00000020	/* EMC_ODT_WRITE */
			0x00000000	/* EMC_ODT_READ */
			0x0000aa88	/* EMC_FBIO_CFG5 */
			0x002c00a0	/* EMC_CFG_DIG_DLL */
			0x00008000	/* EMC_CFG_DIG_DLL_PERIOD */
			0x00078000	/* EMC_DLL_XFORM_DQS4 */
			0x00078000	/* EMC_DLL_XFORM_DQS5 */
			0x00078000	/* EMC_DLL_XFORM_DQS6 */
			0x00078000	/* EMC_DLL_XFORM_DQS7 */
			0x00000000	/* EMC_DLL_XFORM_QUSE4 */
			0x00000000	/* EMC_DLL_XFORM_QUSE5 */
			0x00000000	/* EMC_DLL_XFORM_QUSE6 */
			0x00000000	/* EMC_DLL_XFORM_QUSE7 */
			0x00000000	/* EMC_DLI_TRIM_TXDQS4 */
			0x00000000	/* EMC_DLI_TRIM_TXDQS5 */
			0x00000000	/* EMC_DLI_TRIM_TXDQS6 */
			0x00000000	/* EMC_DLI_TRIM_TXDQS7 */
			0x001112a0	/* EMC_XM2CMDPADCTRL */
			0x00000000	/* EMC_XM2CMDPADCTRL4 */
			0x0000a11c	/* EMC_XM2DQSPADCTRL2 */
			0x00000000	/* EMC_XM2DQPADCTRL2 */
			0x77ffc085	/* EMC_XM2CLKPADCTRL */
			0x81f1f108	/* EMC_XM2COMPPADCTRL */
			0x03037504	/* EMC_XM2VTTGENPADCTRL */
			0x0000003f	/* EMC_XM2VTTGENPADCTRL2 */
			0x0000003f	/* EMC_DSR_VTTGEN_DRV */
			0x00000000	/* EMC_TXDSRVTTGEN */
			0x02000000	/* EMC_FBIO_SPARE */
			0x00000802	/* EMC_CTT_TERM_CTRL */
			0x00020000	/* EMC_ZCAL_INTERVAL */
			0x00000100	/* EMC_ZCAL_WAIT_CNT */
			0x000c000c	/* EMC_MRS_WAIT_CNT */
			0x000c000c	/* EMC_MRS_WAIT_CNT2 */
			0x00000000	/* EMC_AUTO_CAL_CONFIG2 */
			0x00000000	/* EMC_AUTO_CAL_CONFIG3 */
			0x00000000	/* EMC_CTT */
			0x00000000	/* EMC_CTT_DURATION */
			0x80000d22	/* EMC_DYN_SELF_REF_CONTROL */
			0x1f7df7df	/* EMC_CA_TRAINING_TIMING_CNTL1 */
			0x0000001f	/* EMC_CA_TRAINING_TIMING_CNTL2 */
			0x00040320	/* EMC_SEL_DPD_CTRL */
			0x00000000	/* EMC_CDB_CNTL_1 */
			0x00000004	/* EMC_FBIO_CFG6 */
			0x00000007	/* EMC_QUSE */
			0x00000004	/* EMC_EINPUT */
			0x00000004	/* EMC_EINPUT_DURATION */
			0x00078000	/* EMC_DLL_XFORM_DQS0 */
			0x00000009	/* EMC_QSAFE */
			0x00000000	/* EMC_DLL_XFORM_QUSE0 */
			0x0000000d	/* EMC_RDV */
			0x00249249	/* EMC_XM2DQSPADCTRL4 */
			0x20820800	/* EMC_XM2DQSPADCTRL3 */
			0x0007c000	/* EMC_DLL_XFORM_DQ0 */
			0xa0f10f0f	/* EMC_AUTO_CAL_CONFIG */
			0x00000000	/* EMC_DLL_XFORM_ADDR0 */
			0x00000d0d	/* EMC_XM2CLKPADCTRL2 */
			0x00000000	/* EMC_DLI_TRIM_TXDQS0 */
			0x00000000	/* EMC_DLL_XFORM_ADDR1 */
			0x00000000	/* EMC_DLL_XFORM_ADDR2 */
			0x00078000	/* EMC_DLL_XFORM_DQS1 */
			0x00078000	/* EMC_DLL_XFORM_DQS2 */
			0x00078000	/* EMC_DLL_XFORM_DQS3 */
			0x0007c000	/* EMC_DLL_XFORM_DQ1 */
			0x0007c000	/* EMC_DLL_XFORM_DQ2 */
			0x0007c000	/* EMC_DLL_XFORM_DQ3 */
			0x00000000	/* EMC_DLI_TRIM_TXDQS1 */
			0x00000000	/* EMC_DLI_TRIM_TXDQS2 */
			0x00000000	/* EMC_DLI_TRIM_TXDQS3 */
			0x00000000	/* EMC_DLL_XFORM_QUSE1 */
			0x00000000	/* EMC_DLL_XFORM_QUSE2 */
			0x00000000	/* EMC_DLL_XFORM_QUSE3 */
				>;
			};

			timing-300000000 {
				clock-frequency = <300000000>;

				nvidia,emc-auto-cal-config = <0xa1430000>;
				nvidia,emc-auto-cal-config2 = <0x00000000>;
				nvidia,emc-auto-cal-config3 = <0x00000000>;
				nvidia,emc-auto-cal-interval = <0x001fffff>;
				nvidia,emc-bgbias-ctl0 = <0x00000000>;
				nvidia,emc-cfg = <0x73340000>;
				nvidia,emc-cfg-2 = <0x000008d5>;
				nvidia,emc-ctt-term-ctrl = <0x00000802>;
				nvidia,emc-mode-1 = <0x80100002>;
				nvidia,emc-mode-2 = <0x80200000>;
				nvidia,emc-mode-4 = <0x00000000>;
				nvidia,emc-mode-reset = <0x80000321>;
				nvidia,emc-mrs-wait-cnt = <0x0174000c>;
				nvidia,emc-sel-dpd-ctrl = <0x00040128>;
				nvidia,emc-xm2dqspadctrl2 = <0x01231339>;
				nvidia,emc-zcal-cnt-long = <0x00000042>;
				nvidia,emc-zcal-interval = <0x00020000>;

				nvidia,emc-configuration = <
			0x0000000d	/* EMC_RC */
			0x0000004c	/* EMC_RFC */
			0x00000000	/* EMC_RFC_SLR */
			0x00000009	/* EMC_RAS */
			0x00000003	/* EMC_RP */
			0x00000004	/* EMC_R2W */
			0x00000008	/* EMC_W2R */
			0x00000002	/* EMC_R2P */
			0x00000009	/* EMC_W2P */
			0x00000003	/* EMC_RD_RCD */
			0x00000003	/* EMC_WR_RCD */
			0x00000002	/* EMC_RRD */
			0x00000001	/* EMC_REXT */
			0x00000000	/* EMC_WEXT */
			0x00000004	/* EMC_WDV */
			0x0000000f	/* EMC_WDV_MASK */
			0x00000006	/* EMC_IBDLY */
			0x00010000	/* EMC_PUTERM_EXTRA */
			0x00000000	/* EMC_CDB_CNTL_2 */
			0x00000004	/* EMC_QRST */
			0x0000000f	/* EMC_RDV_MASK */
			0x000008e4	/* EMC_REFRESH */
			0x00000000	/* EMC_BURST_REFRESH_NUM */
			0x00000239	/* EMC_PRE_REFRESH_REQ_CNT */
			0x00000001	/* EMC_PDEX2WR */
			0x00000008	/* EMC_PDEX2RD */
			0x00000001	/* EMC_PCHG2PDEN */
			0x00000000	/* EMC_ACT2PDEN */
			0x0000004a	/* EMC_AR2PDEN */
			0x0000000e	/* EMC_RW2PDEN */
			0x00000051	/* EMC_TXSR */
			0x00000200	/* EMC_TXSRDLL */
			0x00000004	/* EMC_TCKE */
			0x00000004	/* EMC_TCKESR */
			0x00000004	/* EMC_TPD */
			0x0000000c	/* EMC_TFAW */
			0x00000000	/* EMC_TRPAB */
			0x00000004	/* EMC_TCLKSTABLE */
			0x00000005	/* EMC_TCLKSTOP */
			0x00000924	/* EMC_TREFBW */
			0x00000000	/* EMC_QUSE_EXTRA */
			0x00000020	/* EMC_ODT_WRITE */
			0x00000000	/* EMC_ODT_READ */
			0x00005088	/* EMC_FBIO_CFG5 */
			0x002c00a0	/* EMC_CFG_DIG_DLL */
			0x00008000	/* EMC_CFG_DIG_DLL_PERIOD */
			0x00038000	/* EMC_DLL_XFORM_DQS4 */
			0x00038000	/* EMC_DLL_XFORM_DQS5 */
			0x00038000	/* EMC_DLL_XFORM_DQS6 */
			0x00038000	/* EMC_DLL_XFORM_DQS7 */
			0x00000000	/* EMC_DLL_XFORM_QUSE4 */
			0x00000000	/* EMC_DLL_XFORM_QUSE5 */
			0x00000000	/* EMC_DLL_XFORM_QUSE6 */
			0x00000000	/* EMC_DLL_XFORM_QUSE7 */
			0x00000000	/* EMC_DLI_TRIM_TXDQS4 */
			0x00000000	/* EMC_DLI_TRIM_TXDQS5 */
			0x00000000	/* EMC_DLI_TRIM_TXDQS6 */
			0x00000000	/* EMC_DLI_TRIM_TXDQS7 */
			0x001112a0	/* EMC_XM2CMDPADCTRL */
			0x00000000	/* EMC_XM2CMDPADCTRL4 */
			0x0001013d	/* EMC_XM2DQSPADCTRL2 */
			0x00000000	/* EMC_XM2DQPADCTRL2 */
			0x77ffc085	/* EMC_XM2CLKPADCTRL */
			0x81f1f108	/* EMC_XM2COMPPADCTRL */
			0x03037504	/* EMC_XM2VTTGENPADCTRL */
			0x00000000	/* EMC_XM2VTTGENPADCTRL2 */
			0x0000003f	/* EMC_DSR_VTTGEN_DRV */
			0x00000000	/* EMC_TXDSRVTTGEN */
			0x02000000	/* EMC_FBIO_SPARE */
			0x00000802	/* EMC_CTT_TERM_CTRL */
			0x00020000	/* EMC_ZCAL_INTERVAL */
			0x00000100	/* EMC_ZCAL_WAIT_CNT */
			0x0174000c	/* EMC_MRS_WAIT_CNT */
			0x0174000c	/* EMC_MRS_WAIT_CNT2 */
			0x00000000	/* EMC_AUTO_CAL_CONFIG2 */
			0x00000000	/* EMC_AUTO_CAL_CONFIG3 */
			0x00000000	/* EMC_CTT */
			0x00000000	/* EMC_CTT_DURATION */
			0x800012d7	/* EMC_DYN_SELF_REF_CONTROL */
			0x1f7df7df	/* EMC_CA_TRAINING_TIMING_CNTL1 */
			0x0000001f	/* EMC_CA_TRAINING_TIMING_CNTL2 */
			0x00040320	/* EMC_SEL_DPD_CTRL */
			0x00000000	/* EMC_CDB_CNTL_1 */
			0x00000004	/* EMC_FBIO_CFG6 */
			0x00000006	/* EMC_QUSE */
			0x00000005	/* EMC_EINPUT */
			0x00000004	/* EMC_EINPUT_DURATION */
			0x00038000	/* EMC_DLL_XFORM_DQS0 */
			0x0000000b	/* EMC_QSAFE */
			0x00000000	/* EMC_DLL_XFORM_QUSE0 */
			0x0000000d	/* EMC_RDV */
			0x00249249	/* EMC_XM2DQSPADCTRL4 */
			0x20820800	/* EMC_XM2DQSPADCTRL3 */
			0x00040000	/* EMC_DLL_XFORM_DQ0 */
			0xa0f10f0f	/* EMC_AUTO_CAL_CONFIG */
			0x00000000	/* EMC_DLL_XFORM_ADDR0 */
			0x00000e0e	/* EMC_XM2CLKPADCTRL2 */
			0x00000000	/* EMC_DLI_TRIM_TXDQS0 */
			0x00004000	/* EMC_DLL_XFORM_ADDR1 */
			0x00000000	/* EMC_DLL_XFORM_ADDR2 */
			0x00038000	/* EMC_DLL_XFORM_DQS1 */
			0x00038000	/* EMC_DLL_XFORM_DQS2 */
			0x00038000	/* EMC_DLL_XFORM_DQS3 */
			0x00040000	/* EMC_DLL_XFORM_DQ1 */
			0x00040000	/* EMC_DLL_XFORM_DQ2 */
			0x00040000	/* EMC_DLL_XFORM_DQ3 */
			0x00000000	/* EMC_DLI_TRIM_TXDQS1 */
			0x00000000	/* EMC_DLI_TRIM_TXDQS2 */
			0x00000000	/* EMC_DLI_TRIM_TXDQS3 */
			0x00000000	/* EMC_DLL_XFORM_QUSE1 */
			0x00000000	/* EMC_DLL_XFORM_QUSE2 */
			0x00000000	/* EMC_DLL_XFORM_QUSE3 */
				>;
			};

			timing-408000000 {
				clock-frequency = <408000000>;

				nvidia,emc-auto-cal-config = <0xa1430000>;
				nvidia,emc-auto-cal-config2 = <0x00000000>;
				nvidia,emc-auto-cal-config3 = <0x00000000>;
				nvidia,emc-auto-cal-interval = <0x001fffff>;
				nvidia,emc-bgbias-ctl0 = <0x00000000>;
				nvidia,emc-cfg = <0x73300000>;
				nvidia,emc-cfg-2 = <0x0000089d>;
				nvidia,emc-ctt-term-ctrl = <0x00000802>;
				nvidia,emc-mode-1 = <0x80100002>;
				nvidia,emc-mode-2 = <0x80200048>;
				nvidia,emc-mode-4 = <0x00000000>;
				nvidia,emc-mode-reset = <0x80000941>;
				nvidia,emc-mrs-wait-cnt = <0x013a000c>;
				nvidia,emc-sel-dpd-ctrl = <0x00040008>;
				nvidia,emc-xm2dqspadctrl2 = <0x0123133d>;
				nvidia,emc-zcal-cnt-long = <0x00000042>;
				nvidia,emc-zcal-interval = <0x00020000>;

				nvidia,emc-configuration = <
			0x00000012	/* EMC_RC */
			0x00000069	/* EMC_RFC */
			0x00000000	/* EMC_RFC_SLR */
			0x0000000d	/* EMC_RAS */
			0x00000004	/* EMC_RP */
			0x00000005	/* EMC_R2W */
			0x00000009	/* EMC_W2R */
			0x00000002	/* EMC_R2P */
			0x0000000c	/* EMC_W2P */
			0x00000004	/* EMC_RD_RCD */
			0x00000004	/* EMC_WR_RCD */
			0x00000002	/* EMC_RRD */
			0x00000001	/* EMC_REXT */
			0x00000000	/* EMC_WEXT */
			0x00000004	/* EMC_WDV */
			0x0000000f	/* EMC_WDV_MASK */
			0x00000006	/* EMC_IBDLY */
			0x00010000	/* EMC_PUTERM_EXTRA */
			0x00000000	/* EMC_CDB_CNTL_2 */
			0x00000004	/* EMC_QRST */
			0x00000010	/* EMC_RDV_MASK */
			0x00000c2e	/* EMC_REFRESH */
			0x00000000	/* EMC_BURST_REFRESH_NUM */
			0x0000030b	/* EMC_PRE_REFRESH_REQ_CNT */
			0x00000001	/* EMC_PDEX2WR */
			0x00000008	/* EMC_PDEX2RD */
			0x00000001	/* EMC_PCHG2PDEN */
			0x00000000	/* EMC_ACT2PDEN */
			0x00000066	/* EMC_AR2PDEN */
			0x00000011	/* EMC_RW2PDEN */
			0x0000006f	/* EMC_TXSR */
			0x00000200	/* EMC_TXSRDLL */
			0x00000004	/* EMC_TCKE */
			0x00000004	/* EMC_TCKESR */
			0x00000004	/* EMC_TPD */
			0x00000011	/* EMC_TFAW */
			0x00000000	/* EMC_TRPAB */
			0x00000004	/* EMC_TCLKSTABLE */
			0x00000005	/* EMC_TCLKSTOP */
			0x00000c6f	/* EMC_TREFBW */
			0x00000000	/* EMC_QUSE_EXTRA */
			0x00000020	/* EMC_ODT_WRITE */
			0x00000000	/* EMC_ODT_READ */
			0x00005088	/* EMC_FBIO_CFG5 */
			0x002c0080	/* EMC_CFG_DIG_DLL */
			0x00008000	/* EMC_CFG_DIG_DLL_PERIOD */
			0x00028000	/* EMC_DLL_XFORM_DQS4 */
			0x00028000	/* EMC_DLL_XFORM_DQS5 */
			0x00028000	/* EMC_DLL_XFORM_DQS6 */
			0x00028000	/* EMC_DLL_XFORM_DQS7 */
			0x00020000	/* EMC_DLL_XFORM_QUSE4 */
			0x00020000	/* EMC_DLL_XFORM_QUSE5 */
			0x00020000	/* EMC_DLL_XFORM_QUSE6 */
			0x00020000	/* EMC_DLL_XFORM_QUSE7 */
			0x00000000	/* EMC_DLI_TRIM_TXDQS4 */
			0x00000000	/* EMC_DLI_TRIM_TXDQS5 */
			0x00000000	/* EMC_DLI_TRIM_TXDQS6 */
			0x00000000	/* EMC_DLI_TRIM_TXDQS7 */
			0x001112a0	/* EMC_XM2CMDPADCTRL */
			0x00000000	/* EMC_XM2CMDPADCTRL4 */
			0x0001013d	/* EMC_XM2DQSPADCTRL2 */
			0x00000000	/* EMC_XM2DQPADCTRL2 */
			0x77ffc085	/* EMC_XM2CLKPADCTRL */
			0x81f1f108	/* EMC_XM2COMPPADCTRL */
			0x03037504	/* EMC_XM2VTTGENPADCTRL */
			0x00000000	/* EMC_XM2VTTGENPADCTRL2 */
			0x0000003f	/* EMC_DSR_VTTGEN_DRV */
			0x00000000	/* EMC_TXDSRVTTGEN */
			0x02000000	/* EMC_FBIO_SPARE */
			0x00000802	/* EMC_CTT_TERM_CTRL */
			0x00020000	/* EMC_ZCAL_INTERVAL */
			0x00000100	/* EMC_ZCAL_WAIT_CNT */
			0x0158000c	/* EMC_MRS_WAIT_CNT */
			0x0158000c	/* EMC_MRS_WAIT_CNT2 */
			0x00000000	/* EMC_AUTO_CAL_CONFIG2 */
			0x00000000	/* EMC_AUTO_CAL_CONFIG3 */
			0x00000000	/* EMC_CTT */
			0x00000000	/* EMC_CTT_DURATION */
			0x80001941	/* EMC_DYN_SELF_REF_CONTROL */
			0x1f7df7df	/* EMC_CA_TRAINING_TIMING_CNTL1 */
			0x0000001f	/* EMC_CA_TRAINING_TIMING_CNTL2 */
			0x00040320	/* EMC_SEL_DPD_CTRL */
			0x00000000	/* EMC_CDB_CNTL_1 */
			0x00000004	/* EMC_FBIO_CFG6 */
			0x00000006	/* EMC_QUSE */
			0x00000005	/* EMC_EINPUT */
			0x00000004	/* EMC_EINPUT_DURATION */
			0x00028000	/* EMC_DLL_XFORM_DQS0 */
			0x0000000c	/* EMC_QSAFE */
			0x00020000	/* EMC_DLL_XFORM_QUSE0 */
			0x0000000e	/* EMC_RDV */
			0x00249249	/* EMC_XM2DQSPADCTRL4 */
			0x20820800	/* EMC_XM2DQSPADCTRL3 */
			0x00030000	/* EMC_DLL_XFORM_DQ0 */
			0xa0f10f0f	/* EMC_AUTO_CAL_CONFIG */
			0x00000000	/* EMC_DLL_XFORM_ADDR0 */
			0x00000606	/* EMC_XM2CLKPADCTRL2 */
			0x00000000	/* EMC_DLI_TRIM_TXDQS0 */
			0x00000000	/* EMC_DLL_XFORM_ADDR1 */
			0x00000000	/* EMC_DLL_XFORM_ADDR2 */
			0x00028000	/* EMC_DLL_XFORM_DQS1 */
			0x00028000	/* EMC_DLL_XFORM_DQS2 */
			0x00028000	/* EMC_DLL_XFORM_DQS3 */
			0x00030000	/* EMC_DLL_XFORM_DQ1 */
			0x00030000	/* EMC_DLL_XFORM_DQ2 */
			0x00030000	/* EMC_DLL_XFORM_DQ3 */
			0x00000000	/* EMC_DLI_TRIM_TXDQS1 */
			0x00000000	/* EMC_DLI_TRIM_TXDQS2 */
			0x00000000	/* EMC_DLI_TRIM_TXDQS3 */
			0x00020000	/* EMC_DLL_XFORM_QUSE1 */
			0x00020000	/* EMC_DLL_XFORM_QUSE2 */
			0x00020000	/* EMC_DLL_XFORM_QUSE3 */
				>;
			};

			timing-600000000 {
				clock-frequency = <600000000>;

				nvidia,emc-auto-cal-config = <0xa1430000>;
				nvidia,emc-auto-cal-config2 = <0x00000000>;
				nvidia,emc-auto-cal-config3 = <0x00000000>;
				nvidia,emc-auto-cal-interval = <0x001fffff>;
				nvidia,emc-bgbias-ctl0 = <0x00000000>;
				nvidia,emc-cfg = <0x73300000>;
				nvidia,emc-cfg-2 = <0x0000089d>;
				nvidia,emc-ctt-term-ctrl = <0x00000802>;
				nvidia,emc-mode-1 = <0x80100002>;
				nvidia,emc-mode-2 = <0x80200010>;
				nvidia,emc-mode-4 = <0x00000000>;
				nvidia,emc-mode-reset = <0x80000b61>;
				nvidia,emc-mrs-wait-cnt = <0x0128000c>;
				nvidia,emc-sel-dpd-ctrl = <0x00040008>;
				nvidia,emc-xm2dqspadctrl2 = <0x0121113d>;
				nvidia,emc-zcal-cnt-long = <0x00000042>;
				nvidia,emc-zcal-interval = <0x00020000>;

				nvidia,emc-configuration = <
			0x0000001c	/* EMC_RC */
			0x0000009a	/* EMC_RFC */
			0x00000000	/* EMC_RFC_SLR */
			0x00000013	/* EMC_RAS */
			0x00000007	/* EMC_RP */
			0x00000007	/* EMC_R2W */
			0x0000000b	/* EMC_W2R */
			0x00000003	/* EMC_R2P */
			0x00000010	/* EMC_W2P */
			0x00000007	/* EMC_RD_RCD */
			0x00000007	/* EMC_WR_RCD */
			0x00000002	/* EMC_RRD */
			0x00000001	/* EMC_REXT */
			0x00000000	/* EMC_WEXT */
			0x00000005	/* EMC_WDV */
			0x0000000f	/* EMC_WDV_MASK */
			0x0000000a	/* EMC_IBDLY */
			0x00010000	/* EMC_PUTERM_EXTRA */
			0x00000000	/* EMC_CDB_CNTL_2 */
			0x00000007	/* EMC_QRST */
			0x00000014	/* EMC_RDV_MASK */
			0x00001208	/* EMC_REFRESH */
			0x00000000	/* EMC_BURST_REFRESH_NUM */
			0x00000482	/* EMC_PRE_REFRESH_REQ_CNT */
			0x00000002	/* EMC_PDEX2WR */
			0x0000000d	/* EMC_PDEX2RD */
			0x00000001	/* EMC_PCHG2PDEN */
			0x00000000	/* EMC_ACT2PDEN */
			0x00000096	/* EMC_AR2PDEN */
			0x00000015	/* EMC_RW2PDEN */
			0x000000a2	/* EMC_TXSR */
			0x00000200	/* EMC_TXSRDLL */
			0x00000004	/* EMC_TCKE */
			0x00000004	/* EMC_TCKESR */
			0x00000004	/* EMC_TPD */
			0x00000018	/* EMC_TFAW */
			0x00000000	/* EMC_TRPAB */
			0x00000005	/* EMC_TCLKSTABLE */
			0x00000006	/* EMC_TCLKSTOP */
			0x00001248	/* EMC_TREFBW */
			0x0000000a	/* EMC_QUSE_EXTRA */
			0x00000020	/* EMC_ODT_WRITE */
			0x00000000	/* EMC_ODT_READ */
			0x0000ba88	/* EMC_FBIO_CFG5 */
			0xf00e0191	/* EMC_CFG_DIG_DLL */
			0x00008000	/* EMC_CFG_DIG_DLL_PERIOD */
			0x00000009	/* EMC_DLL_XFORM_DQS4 */
			0x00000009	/* EMC_DLL_XFORM_DQS5 */
			0x00000009	/* EMC_DLL_XFORM_DQS6 */
			0x00000009	/* EMC_DLL_XFORM_DQS7 */
			0x00000000	/* EMC_DLL_XFORM_QUSE4 */
			0x00000000	/* EMC_DLL_XFORM_QUSE5 */
			0x00000000	/* EMC_DLL_XFORM_QUSE6 */
			0x00000000	/* EMC_DLL_XFORM_QUSE7 */
			0x00000000	/* EMC_DLI_TRIM_TXDQS4 */
			0x00000000	/* EMC_DLI_TRIM_TXDQS5 */
			0x00000000	/* EMC_DLI_TRIM_TXDQS6 */
			0x00000000	/* EMC_DLI_TRIM_TXDQS7 */
			0x001112a0	/* EMC_XM2CMDPADCTRL */
			0x00000000	/* EMC_XM2CMDPADCTRL4 */
			0x0000013d	/* EMC_XM2DQSPADCTRL2 */
			0x00000000	/* EMC_XM2DQPADCTRL2 */
			0x77ffc085	/* EMC_XM2CLKPADCTRL */
			0x81f1f108	/* EMC_XM2COMPPADCTRL */
			0x07077504	/* EMC_XM2VTTGENPADCTRL */
			0x00000000	/* EMC_XM2VTTGENPADCTRL2 */
			0x0000003f	/* EMC_DSR_VTTGEN_DRV */
			0x00000000	/* EMC_TXDSRVTTGEN */
			0x02000000	/* EMC_FBIO_SPARE */
			0x00000802	/* EMC_CTT_TERM_CTRL */
			0x00020000	/* EMC_ZCAL_INTERVAL */
			0x00000100	/* EMC_ZCAL_WAIT_CNT */
			0x0128000c	/* EMC_MRS_WAIT_CNT */
			0x0128000c	/* EMC_MRS_WAIT_CNT2 */
			0x00000000	/* EMC_AUTO_CAL_CONFIG2 */
			0x00000000	/* EMC_AUTO_CAL_CONFIG3 */
			0x00000000	/* EMC_CTT */
			0x00000000	/* EMC_CTT_DURATION */
			0x800024aa	/* EMC_DYN_SELF_REF_CONTROL */
			0x1f7df7df	/* EMC_CA_TRAINING_TIMING_CNTL1 */
			0x0000001f	/* EMC_CA_TRAINING_TIMING_CNTL2 */
			0x00040320	/* EMC_SEL_DPD_CTRL */
			0x00000000	/* EMC_CDB_CNTL_1 */
			0x00000004	/* EMC_FBIO_CFG6 */
			0x0000000a	/* EMC_QUSE */
			0x00000008	/* EMC_EINPUT */
			0x00000004	/* EMC_EINPUT_DURATION */
			0x00000009	/* EMC_DLL_XFORM_DQS0 */
			0x0000000c	/* EMC_QSAFE */
			0x00000000	/* EMC_DLL_XFORM_QUSE0 */
			0x00000012	/* EMC_RDV */
			0x00249249	/* EMC_XM2DQSPADCTRL4 */
			0x20820800	/* EMC_XM2DQSPADCTRL3 */
			0x0000000a	/* EMC_DLL_XFORM_DQ0 */
			0xa0f10f0f	/* EMC_AUTO_CAL_CONFIG */
			0x00000000	/* EMC_DLL_XFORM_ADDR0 */
			0x00000c0c	/* EMC_XM2CLKPADCTRL2 */
			0x00000000	/* EMC_DLI_TRIM_TXDQS0 */
			0x00000000	/* EMC_DLL_XFORM_ADDR1 */
			0x00000000	/* EMC_DLL_XFORM_ADDR2 */
			0x00000009	/* EMC_DLL_XFORM_DQS1 */
			0x00000009	/* EMC_DLL_XFORM_DQS2 */
			0x00000009	/* EMC_DLL_XFORM_DQS3 */
			0x0000000b	/* EMC_DLL_XFORM_DQ1 */
			0x0000000a	/* EMC_DLL_XFORM_DQ2 */
			0x0000000a	/* EMC_DLL_XFORM_DQ3 */
			0x00000000	/* EMC_DLI_TRIM_TXDQS1 */
			0x00000000	/* EMC_DLI_TRIM_TXDQS2 */
			0x00000000	/* EMC_DLI_TRIM_TXDQS3 */
			0x00000000	/* EMC_DLL_XFORM_QUSE1 */
			0x00000000	/* EMC_DLL_XFORM_QUSE2 */
			0x00000000	/* EMC_DLL_XFORM_QUSE3 */
				>;
			};

			timing-792000000 {
				clock-frequency = <792000000>;

				nvidia,emc-auto-cal-config = <0xa1430000>;
				nvidia,emc-auto-cal-config2 = <0x00000000>;
				nvidia,emc-auto-cal-config3 = <0x00000000>;
				nvidia,emc-auto-cal-interval = <0x001fffff>;
				nvidia,emc-bgbias-ctl0 = <0x00000000>;
				nvidia,emc-cfg = <0x73300000>;
				nvidia,emc-cfg-2 = <0x0080089d>;
				nvidia,emc-ctt-term-ctrl = <0x00000802>;
				nvidia,emc-mode-1 = <0x80100002>;
				nvidia,emc-mode-2 = <0x80200418>;
				nvidia,emc-mode-4 = <0x00000000>;
				nvidia,emc-mode-reset = <0x80000d71>;
				nvidia,emc-mrs-wait-cnt = <0x00f8000c>;
				nvidia,emc-sel-dpd-ctrl = <0x00040000>;
				nvidia,emc-xm2dqspadctrl2 = <0x0120113d>;
				nvidia,emc-zcal-cnt-long = <0x00000042>;
				nvidia,emc-zcal-interval = <0x00020000>;

				nvidia,emc-configuration = <
			0x00000025	/* EMC_RC */
			0x000000cc	/* EMC_RFC */
			0x00000000	/* EMC_RFC_SLR */
			0x0000001a	/* EMC_RAS */
			0x00000009	/* EMC_RP */
			0x00000008	/* EMC_R2W */
			0x0000000d	/* EMC_W2R */
			0x00000004	/* EMC_R2P */
			0x00000013	/* EMC_W2P */
			0x00000009	/* EMC_RD_RCD */
			0x00000009	/* EMC_WR_RCD */
			0x00000003	/* EMC_RRD */
			0x00000001	/* EMC_REXT */
			0x00000000	/* EMC_WEXT */
			0x00000006	/* EMC_WDV */
			0x0000000f	/* EMC_WDV_MASK */
			0x0000000b	/* EMC_IBDLY */
			0x00010000	/* EMC_PUTERM_EXTRA */
			0x00000000	/* EMC_CDB_CNTL_2 */
			0x00000008	/* EMC_QRST */
			0x00000016	/* EMC_RDV_MASK */
			0x000017e1	/* EMC_REFRESH */
			0x00000000	/* EMC_BURST_REFRESH_NUM */
			0x000005f8	/* EMC_PRE_REFRESH_REQ_CNT */
			0x00000003	/* EMC_PDEX2WR */
			0x00000011	/* EMC_PDEX2RD */
			0x00000001	/* EMC_PCHG2PDEN */
			0x00000000	/* EMC_ACT2PDEN */
			0x000000c6	/* EMC_AR2PDEN */
			0x00000018	/* EMC_RW2PDEN */
			0x000000d6	/* EMC_TXSR */
			0x00000200	/* EMC_TXSRDLL */
			0x00000005	/* EMC_TCKE */
			0x00000005	/* EMC_TCKESR */
			0x00000005	/* EMC_TPD */
			0x00000020	/* EMC_TFAW */
			0x00000000	/* EMC_TRPAB */
			0x00000007	/* EMC_TCLKSTABLE */
			0x00000008	/* EMC_TCLKSTOP */
			0x00001822	/* EMC_TREFBW */
			0x00000000	/* EMC_QUSE_EXTRA */
			0x80000000	/* EMC_ODT_WRITE */
			0x00000000	/* EMC_ODT_READ */
			0x00005088	/* EMC_FBIO_CFG5 */
			0xf0070191	/* EMC_CFG_DIG_DLL */
			0x00008000	/* EMC_CFG_DIG_DLL_PERIOD */
			0x00000008	/* EMC_DLL_XFORM_DQS4 */
			0x00000008	/* EMC_DLL_XFORM_DQS5 */
			0x00000008	/* EMC_DLL_XFORM_DQS6 */
			0x00000008	/* EMC_DLL_XFORM_DQS7 */
			0x00028000	/* EMC_DLL_XFORM_QUSE4 */
			0x00028000	/* EMC_DLL_XFORM_QUSE5 */
			0x00028000	/* EMC_DLL_XFORM_QUSE6 */
			0x00028000	/* EMC_DLL_XFORM_QUSE7 */
			0x00000000	/* EMC_DLI_TRIM_TXDQS4 */
			0x00000000	/* EMC_DLI_TRIM_TXDQS5 */
			0x00000000	/* EMC_DLI_TRIM_TXDQS6 */
			0x00000000	/* EMC_DLI_TRIM_TXDQS7 */
			0x001112a0	/* EMC_XM2CMDPADCTRL */
			0x00000000	/* EMC_XM2CMDPADCTRL4 */
			0x0000013d	/* EMC_XM2DQSPADCTRL2 */
			0x00000000	/* EMC_XM2DQPADCTRL2 */
			0x77ffc085	/* EMC_XM2CLKPADCTRL */
			0x81f1f108	/* EMC_XM2COMPPADCTRL */
			0x07077504	/* EMC_XM2VTTGENPADCTRL */
			0x00000000	/* EMC_XM2VTTGENPADCTRL2 */
			0x0000003f	/* EMC_DSR_VTTGEN_DRV */
			0x00000000	/* EMC_TXDSRVTTGEN */
			0x02000000	/* EMC_FBIO_SPARE */
			0x00000802	/* EMC_CTT_TERM_CTRL */
			0x00020000	/* EMC_ZCAL_INTERVAL */
			0x00000100	/* EMC_ZCAL_WAIT_CNT */
			0x00f8000c	/* EMC_MRS_WAIT_CNT */
			0x00f8000c	/* EMC_MRS_WAIT_CNT2 */
			0x00000000	/* EMC_AUTO_CAL_CONFIG2 */
			0x00000000	/* EMC_AUTO_CAL_CONFIG3 */
			0x00000000	/* EMC_CTT */
			0x00000000	/* EMC_CTT_DURATION */
			0x80003012	/* EMC_DYN_SELF_REF_CONTROL */
			0x1f7df7df	/* EMC_CA_TRAINING_TIMING_CNTL1 */
			0x0000001f	/* EMC_CA_TRAINING_TIMING_CNTL2 */
			0x00040000	/* EMC_SEL_DPD_CTRL */
			0x00000000	/* EMC_CDB_CNTL_1 */
			0x00000006	/* EMC_FBIO_CFG6 */
			0x0000000a	/* EMC_QUSE */
			0x00000008	/* EMC_EINPUT */
			0x00000006	/* EMC_EINPUT_DURATION */
			0x00000008	/* EMC_DLL_XFORM_DQS0 */
			0x0000000d	/* EMC_QSAFE */
			0x00028000	/* EMC_DLL_XFORM_QUSE0 */
			0x00000014	/* EMC_RDV */
			0x00249249	/* EMC_XM2DQSPADCTRL4 */
			0x20820800	/* EMC_XM2DQSPADCTRL3 */
			0x0000000b	/* EMC_DLL_XFORM_DQ0 */
			0xa0f10f0f	/* EMC_AUTO_CAL_CONFIG */
			0x00000000	/* EMC_DLL_XFORM_ADDR0 */
			0x00000a0a	/* EMC_XM2CLKPADCTRL2 */
			0x00000000	/* EMC_DLI_TRIM_TXDQS0 */
			0x00000000	/* EMC_DLL_XFORM_ADDR1 */
			0x00000000	/* EMC_DLL_XFORM_ADDR2 */
			0x00000007	/* EMC_DLL_XFORM_DQS1 */
			0x00000009	/* EMC_DLL_XFORM_DQS2 */
			0x00000008	/* EMC_DLL_XFORM_DQS3 */
			0x0000000b	/* EMC_DLL_XFORM_DQ1 */
			0x0000000b	/* EMC_DLL_XFORM_DQ2 */
			0x0000000b	/* EMC_DLL_XFORM_DQ3 */
			0x00000000	/* EMC_DLI_TRIM_TXDQS1 */
			0x00000000	/* EMC_DLI_TRIM_TXDQS2 */
			0x00000000	/* EMC_DLI_TRIM_TXDQS3 */
			0x00028000	/* EMC_DLL_XFORM_QUSE1 */
			0x00028000	/* EMC_DLL_XFORM_QUSE2 */
			0x00028000	/* EMC_DLL_XFORM_QUSE3 */
				>;
			};
		};

	};

//	opp-table-actmon {
//		/delete-node/ opp-924000000;
//		/delete-node/ opp-1200000000;
//	};

//	opp-table-emc {
//		/delete-node/ opp-924000000-1100;
//		/delete-node/ opp-1200000000-1100;
//	};
};
